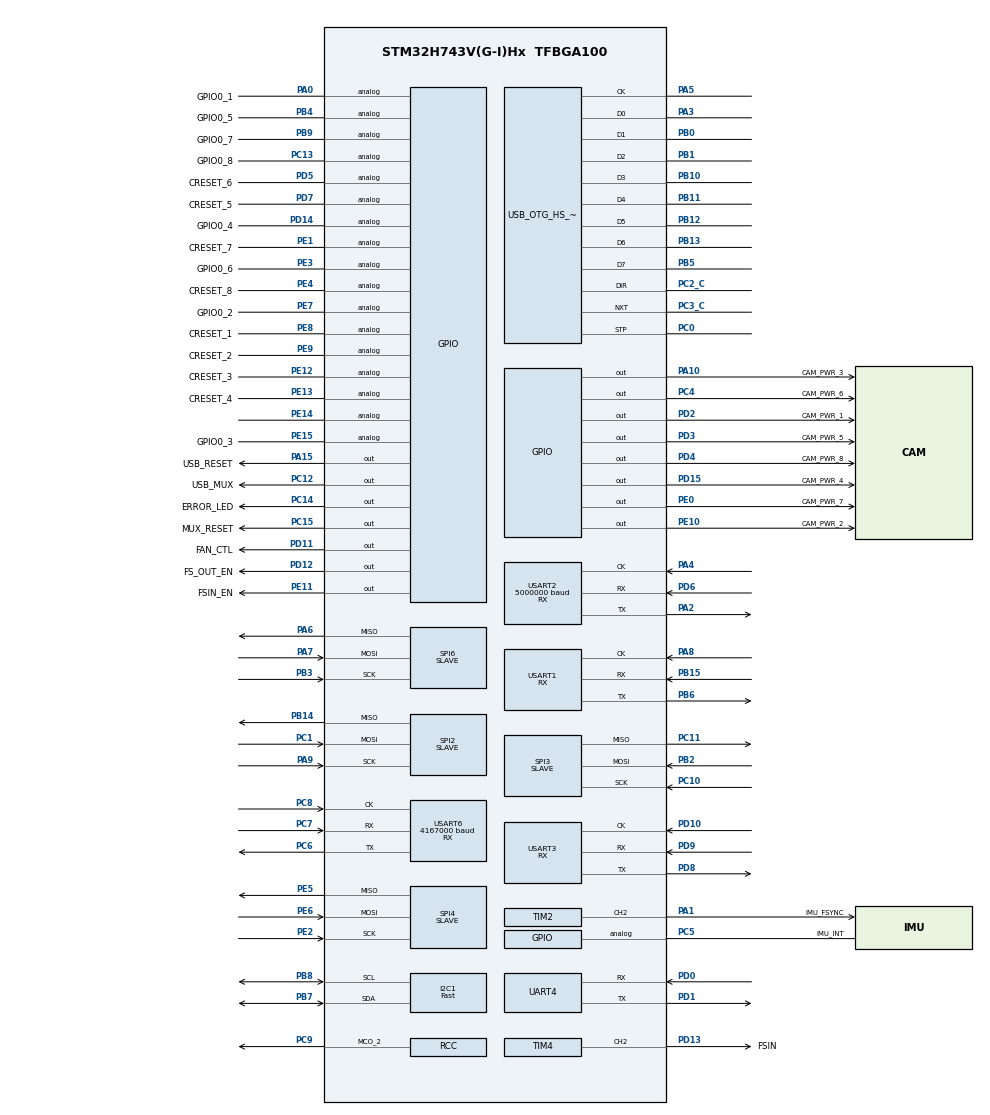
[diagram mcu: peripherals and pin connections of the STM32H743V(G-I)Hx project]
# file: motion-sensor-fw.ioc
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Bdma.Request0=SPI6_RX
Bdma.RequestsNb=1
Bdma.SPI6_RX.0.Direction=DMA_PERIPH_TO_MEMORY
Bdma.SPI6_RX.0.EventEnable=DISABLE
Bdma.SPI6_RX.0.Instance=BDMA_Channel0
Bdma.SPI6_RX.0.MemDataAlignment=DMA_MDATAALIGN_BYTE
Bdma.SPI6_RX.0.MemInc=DMA_MINC_ENABLE
Bdma.SPI6_RX.0.Mode=DMA_NORMAL
Bdma.SPI6_RX.0.PeriphDataAlignment=DMA_PDATAALIGN_BYTE
Bdma.SPI6_RX.0.PeriphInc=DMA_PINC_DISABLE
Bdma.SPI6_RX.0.Polarity=HAL_DMAMUX_REQ_GEN_RISING
Bdma.SPI6_RX.0.Priority=DMA_PRIORITY_MEDIUM
Bdma.SPI6_RX.0.RequestNumber=1
Bdma.SPI6_RX.0.SignalID=NONE
Bdma.SPI6_RX.0.SyncEnable=DISABLE
Bdma.SPI6_RX.0.SyncPolarity=HAL_DMAMUX_SYNC_NO_EVENT
Bdma.SPI6_RX.0.SyncRequestNumber=1
Bdma.SPI6_RX.0.SyncSignalID=NONE
CORTEX_M7.default_mode_Activation=1
Dma.MEMTOMEM.8.Direction=DMA_MEMORY_TO_MEMORY
Dma.MEMTOMEM.8.EventEnable=DISABLE
Dma.MEMTOMEM.8.FIFOMode=DMA_FIFOMODE_ENABLE
Dma.MEMTOMEM.8.FIFOThreshold=DMA_FIFO_THRESHOLD_FULL
Dma.MEMTOMEM.8.Instance=DMA2_Stream1
Dma.MEMTOMEM.8.MemBurst=DMA_MBURST_INC4
Dma.MEMTOMEM.8.MemDataAlignment=DMA_MDATAALIGN_WORD
Dma.MEMTOMEM.8.MemInc=DMA_MINC_ENABLE
Dma.MEMTOMEM.8.Mode=DMA_NORMAL
Dma.MEMTOMEM.8.PeriphBurst=DMA_PBURST_INC4
Dma.MEMTOMEM.8.PeriphDataAlignment=DMA_PDATAALIGN_WORD
Dma.MEMTOMEM.8.PeriphInc=DMA_PINC_DISABLE
Dma.MEMTOMEM.8.Polarity=HAL_DMAMUX_REQ_GEN_RISING
Dma.MEMTOMEM.8.Priority=DMA_PRIORITY_MEDIUM
Dma.MEMTOMEM.8.RequestNumber=1
Dma.MEMTOMEM.8.SignalID=NONE
Dma.MEMTOMEM.8.SyncEnable=DISABLE
Dma.MEMTOMEM.8.SyncPolarity=HAL_DMAMUX_SYNC_NO_EVENT
Dma.MEMTOMEM.8.SyncRequestNumber=1
Dma.MEMTOMEM.8.SyncSignalID=NONE
Dma.Request0=UART4_RX
Dma.Request1=UART4_TX
Dma.Request2=SPI2_RX
Dma.Request3=SPI4_RX
Dma.Request4=USART2_RX
Dma.Request5=USART1_RX
Dma.Request6=USART3_RX
Dma.Request7=USART6_RX
Dma.Request8=MEMTOMEM
Dma.Request9=SPI3_RX
Dma.SPI2_RX.2.Direction=DMA_PERIPH_TO_MEMORY
Dma.SPI2_RX.2.EventEnable=DISABLE
Dma.SPI2_RX.2.FIFOMode=DMA_FIFOMODE_DISABLE
Dma.SPI2_RX.2.Instance=DMA1_Stream2
Dma.SPI2_RX.2.MemDataAlignment=DMA_MDATAALIGN_BYTE
Dma.SPI2_RX.2.MemInc=DMA_MINC_ENABLE
Dma.SPI2_RX.2.Mode=DMA_NORMAL
Dma.SPI2_RX.2.PeriphDataAlignment=DMA_PDATAALIGN_BYTE
Dma.SPI2_RX.2.PeriphInc=DMA_PINC_DISABLE
Dma.SPI2_RX.2.Polarity=HAL_DMAMUX_REQ_GEN_RISING
Dma.SPI2_RX.2.Priority=DMA_PRIORITY_MEDIUM
Dma.SPI2_RX.2.RequestNumber=1
Dma.SPI2_RX.2.SignalID=NONE
Dma.SPI2_RX.2.SyncEnable=DISABLE
Dma.SPI2_RX.2.SyncPolarity=HAL_DMAMUX_SYNC_NO_EVENT
Dma.SPI2_RX.2.SyncRequestNumber=1
Dma.SPI2_RX.2.SyncSignalID=NONE
Dma.SPI3_RX.9.Direction=DMA_PERIPH_TO_MEMORY
Dma.SPI3_RX.9.EventEnable=DISABLE
Dma.SPI3_RX.9.FIFOMode=DMA_FIFOMODE_DISABLE
Dma.SPI3_RX.9.Instance=DMA1_Stream3
Dma.SPI3_RX.9.MemDataAlignment=DMA_MDATAALIGN_BYTE
Dma.SPI3_RX.9.MemInc=DMA_MINC_ENABLE
Dma.SPI3_RX.9.Mode=DMA_NORMAL
Dma.SPI3_RX.9.PeriphDataAlignment=DMA_PDATAALIGN_BYTE
Dma.SPI3_RX.9.PeriphInc=DMA_PINC_DISABLE
Dma.SPI3_RX.9.Polarity=HAL_DMAMUX_REQ_GEN_RISING
Dma.SPI3_RX.9.Priority=DMA_PRIORITY_LOW
Dma.SPI3_RX.9.RequestNumber=1
Dma.SPI3_RX.9.SignalID=NONE
Dma.SPI3_RX.9.SyncEnable=DISABLE
Dma.SPI3_RX.9.SyncPolarity=HAL_DMAMUX_SYNC_NO_EVENT
Dma.SPI3_RX.9.SyncRequestNumber=1
Dma.SPI3_RX.9.SyncSignalID=NONE
Dma.SPI4_RX.3.Direction=DMA_PERIPH_TO_MEMORY
Dma.SPI4_RX.3.EventEnable=DISABLE
Dma.SPI4_RX.3.FIFOMode=DMA_FIFOMODE_DISABLE
Dma.SPI4_RX.3.Instance=DMA1_Stream4
Dma.SPI4_RX.3.MemDataAlignment=DMA_MDATAALIGN_BYTE
Dma.SPI4_RX.3.MemInc=DMA_MINC_ENABLE
Dma.SPI4_RX.3.Mode=DMA_NORMAL
Dma.SPI4_RX.3.PeriphDataAlignment=DMA_PDATAALIGN_BYTE
Dma.SPI4_RX.3.PeriphInc=DMA_PINC_DISABLE
Dma.SPI4_RX.3.Polarity=HAL_DMAMUX_REQ_GEN_RISING
Dma.SPI4_RX.3.Priority=DMA_PRIORITY_MEDIUM
Dma.SPI4_RX.3.RequestNumber=1
Dma.SPI4_RX.3.SignalID=NONE
Dma.SPI4_RX.3.SyncEnable=DISABLE
Dma.SPI4_RX.3.SyncPolarity=HAL_DMAMUX_SYNC_NO_EVENT
Dma.SPI4_RX.3.SyncRequestNumber=1
Dma.SPI4_RX.3.SyncSignalID=NONE
Dma.UART4_RX.0.Direction=DMA_PERIPH_TO_MEMORY
Dma.UART4_RX.0.EventEnable=DISABLE
Dma.UART4_RX.0.FIFOMode=DMA_FIFOMODE_DISABLE
Dma.UART4_RX.0.Instance=DMA1_Stream0
Dma.UART4_RX.0.MemDataAlignment=DMA_MDATAALIGN_BYTE
Dma.UART4_RX.0.MemInc=DMA_MINC_ENABLE
Dma.UART4_RX.0.Mode=DMA_NORMAL
Dma.UART4_RX.0.PeriphDataAlignment=DMA_PDATAALIGN_BYTE
Dma.UART4_RX.0.PeriphInc=DMA_PINC_DISABLE
Dma.UART4_RX.0.Polarity=HAL_DMAMUX_REQ_GEN_RISING
Dma.UART4_RX.0.Priority=DMA_PRIORITY_LOW
Dma.UART4_RX.0.RequestNumber=1
Dma.UART4_RX.0.SignalID=NONE
Dma.UART4_RX.0.SyncEnable=DISABLE
Dma.UART4_RX.0.SyncPolarity=HAL_DMAMUX_SYNC_NO_EVENT
Dma.UART4_RX.0.SyncRequestNumber=1
Dma.UART4_RX.0.SyncSignalID=NONE
Dma.UART4_TX.1.Direction=DMA_MEMORY_TO_PERIPH
Dma.UART4_TX.1.EventEnable=DISABLE
Dma.UART4_TX.1.FIFOMode=DMA_FIFOMODE_DISABLE
Dma.UART4_TX.1.Instance=DMA1_Stream1
Dma.UART4_TX.1.MemDataAlignment=DMA_MDATAALIGN_BYTE
Dma.UART4_TX.1.MemInc=DMA_MINC_ENABLE
Dma.UART4_TX.1.Mode=DMA_NORMAL
Dma.UART4_TX.1.PeriphDataAlignment=DMA_PDATAALIGN_BYTE
Dma.UART4_TX.1.PeriphInc=DMA_PINC_DISABLE
Dma.UART4_TX.1.Polarity=HAL_DMAMUX_REQ_GEN_RISING
Dma.UART4_TX.1.Priority=DMA_PRIORITY_LOW
Dma.UART4_TX.1.RequestNumber=1
Dma.UART4_TX.1.SignalID=NONE
Dma.UART4_TX.1.SyncEnable=DISABLE
Dma.UART4_TX.1.SyncPolarity=HAL_DMAMUX_SYNC_NO_EVENT
Dma.UART4_TX.1.SyncRequestNumber=1
Dma.UART4_TX.1.SyncSignalID=NONE
Dma.USART1_RX.5.Direction=DMA_PERIPH_TO_MEMORY
Dma.USART1_RX.5.EventEnable=DISABLE
Dma.USART1_RX.5.FIFOMode=DMA_FIFOMODE_DISABLE
Dma.USART1_RX.5.Instance=DMA1_Stream6
Dma.USART1_RX.5.MemDataAlignment=DMA_MDATAALIGN_BYTE
Dma.USART1_RX.5.MemInc=DMA_MINC_ENABLE
Dma.USART1_RX.5.Mode=DMA_NORMAL
Dma.USART1_RX.5.PeriphDataAlignment=DMA_PDATAALIGN_BYTE
Dma.USART1_RX.5.PeriphInc=DMA_PINC_DISABLE
Dma.USART1_RX.5.Polarity=HAL_DMAMUX_REQ_GEN_RISING
Dma.USART1_RX.5.Priority=DMA_PRIORITY_MEDIUM
Dma.USART1_RX.5.RequestNumber=1
Dma.USART1_RX.5.SignalID=NONE
Dma.USART1_RX.5.SyncEnable=DISABLE
Dma.USART1_RX.5.SyncPolarity=HAL_DMAMUX_SYNC_NO_EVENT
Dma.USART1_RX.5.SyncRequestNumber=1
Dma.USART1_RX.5.SyncSignalID=NONE
Dma.USART2_RX.4.Direction=DMA_PERIPH_TO_MEMORY
Dma.USART2_RX.4.EventEnable=DISABLE
Dma.USART2_RX.4.FIFOMode=DMA_FIFOMODE_DISABLE
Dma.USART2_RX.4.Instance=DMA1_Stream5
Dma.USART2_RX.4.MemDataAlignment=DMA_MDATAALIGN_BYTE
Dma.USART2_RX.4.MemInc=DMA_MINC_ENABLE
Dma.USART2_RX.4.Mode=DMA_NORMAL
Dma.USART2_RX.4.PeriphDataAlignment=DMA_PDATAALIGN_BYTE
Dma.USART2_RX.4.PeriphInc=DMA_PINC_DISABLE
Dma.USART2_RX.4.Polarity=HAL_DMAMUX_REQ_GEN_RISING
Dma.USART2_RX.4.Priority=DMA_PRIORITY_MEDIUM
Dma.USART2_RX.4.RequestNumber=1
Dma.USART2_RX.4.SignalID=NONE
Dma.USART2_RX.4.SyncEnable=DISABLE
Dma.USART2_RX.4.SyncPolarity=HAL_DMAMUX_SYNC_NO_EVENT
Dma.USART2_RX.4.SyncRequestNumber=1
Dma.USART2_RX.4.SyncSignalID=NONE
Dma.USART3_RX.6.Direction=DMA_PERIPH_TO_MEMORY
Dma.USART3_RX.6.EventEnable=DISABLE
Dma.USART3_RX.6.FIFOMode=DMA_FIFOMODE_DISABLE
Dma.USART3_RX.6.Instance=DMA1_Stream7
Dma.USART3_RX.6.MemDataAlignment=DMA_MDATAALIGN_BYTE
Dma.USART3_RX.6.MemInc=DMA_MINC_ENABLE
Dma.USART3_RX.6.Mode=DMA_NORMAL
Dma.USART3_RX.6.PeriphDataAlignment=DMA_PDATAALIGN_BYTE
Dma.USART3_RX.6.PeriphInc=DMA_PINC_DISABLE
Dma.USART3_RX.6.Polarity=HAL_DMAMUX_REQ_GEN_RISING
Dma.USART3_RX.6.Priority=DMA_PRIORITY_MEDIUM
Dma.USART3_RX.6.RequestNumber=1
Dma.USART3_RX.6.SignalID=NONE
Dma.USART3_RX.6.SyncEnable=DISABLE
Dma.USART3_RX.6.SyncPolarity=HAL_DMAMUX_SYNC_NO_EVENT
Dma.USART3_RX.6.SyncRequestNumber=1
Dma.USART3_RX.6.SyncSignalID=NONE
Dma.USART6_RX.7.Direction=DMA_PERIPH_TO_MEMORY
Dma.USART6_RX.7.EventEnable=DISABLE
Dma.USART6_RX.7.FIFOMode=DMA_FIFOMODE_DISABLE
Dma.USART6_RX.7.Instance=DMA2_Stream0
Dma.USART6_RX.7.MemDataAlignment=DMA_MDATAALIGN_BYTE
Dma.USART6_RX.7.MemInc=DMA_MINC_ENABLE
Dma.USART6_RX.7.Mode=DMA_NORMAL
Dma.USART6_RX.7.PeriphDataAlignment=DMA_PDATAALIGN_BYTE
Dma.USART6_RX.7.PeriphInc=DMA_PINC_DISABLE
Dma.USART6_RX.7.Polarity=HAL_DMAMUX_REQ_GEN_RISING
Dma.USART6_RX.7.Priority=DMA_PRIORITY_MEDIUM
Dma.USART6_RX.7.RequestNumber=1
Dma.USART6_RX.7.SignalID=NONE
Dma.USART6_RX.7.SyncEnable=DISABLE
Dma.USART6_RX.7.SyncPolarity=HAL_DMAMUX_SYNC_NO_EVENT
Dma.USART6_RX.7.SyncRequestNumber=1
Dma.USART6_RX.7.SyncSignalID=NONE
I2C1.I2C_Speed_Mode=I2C_Fast
I2C1.Timing=0x00B03FDB
IWDG1.Prescaler=IWDG_PRESCALER_64
IWDG1.Reload=124
IWDG1.Window=4095
Mcu.Family=STM32H7
Mcu.Name=STM32H743V(G-I)Hx
Mcu.Package=TFBGA100
NVIC.BDMA_Channel0_IRQn=true\:0\:0\:false\:false\:true\:false\:true\:true
NVIC.DMA1_Stream0_IRQn=true\:0\:0\:false\:false\:true\:false\:true\:true
NVIC.DMA1_Stream1_IRQn=true\:0\:0\:false\:false\:true\:false\:true\:true
NVIC.DMA1_Stream2_IRQn=true\:0\:0\:false\:false\:true\:false\:true\:true
NVIC.DMA1_Stream3_IRQn=true\:0\:0\:false\:false\:true\:false\:true\:true
NVIC.DMA1_Stream4_IRQn=true\:0\:0\:false\:false\:true\:false\:true\:true
NVIC.DMA1_Stream5_IRQn=true\:0\:0\:false\:false\:true\:false\:true\:true
NVIC.DMA1_Stream6_IRQn=true\:0\:0\:false\:false\:true\:false\:true\:true
NVIC.DMA1_Stream7_IRQn=true\:0\:0\:false\:false\:true\:false\:true\:true
NVIC.DMA2_Stream0_IRQn=true\:0\:0\:false\:false\:true\:false\:true\:true
NVIC.ECC_IRQn=true\:0\:0\:false\:false\:true\:true\:true\:true
NVIC.I2C1_ER_IRQn=true\:0\:0\:false\:false\:true\:true\:true\:true
NVIC.I2C1_EV_IRQn=true\:0\:0\:false\:false\:true\:true\:true\:true
NVIC.OTG_HS_EP1_IN_IRQn=true\:0\:0\:false\:false\:true\:true\:true\:true
NVIC.OTG_HS_EP1_OUT_IRQn=true\:0\:0\:false\:false\:true\:true\:true\:true
NVIC.OTG_HS_IRQn=true\:0\:0\:false\:false\:true\:true\:true\:true
NVIC.PriorityGroup=NVIC_PRIORITYGROUP_4
NVIC.SPI2_IRQn=true\:0\:0\:false\:false\:true\:true\:true\:true
NVIC.SPI3_IRQn=true\:0\:0\:false\:false\:true\:true\:true\:true
NVIC.SPI4_IRQn=true\:0\:0\:false\:false\:true\:true\:true\:true
NVIC.SPI6_IRQn=true\:0\:0\:false\:false\:true\:true\:true\:true
NVIC.TIM15_IRQn=true\:0\:0\:false\:false\:true\:true\:true\:true
NVIC.TIM16_IRQn=true\:3\:0\:true\:false\:true\:true\:true\:true
NVIC.TIM17_IRQn=true\:15\:0\:false\:false\:true\:false\:true\:true
NVIC.TIM4_IRQn=true\:0\:0\:false\:false\:true\:true\:true\:true
NVIC.TIM8_BRK_TIM12_IRQn=true\:0\:0\:false\:false\:true\:true\:true\:true
NVIC.TIM8_TRG_COM_TIM14_IRQn=true\:0\:0\:false\:false\:true\:true\:true\:true
NVIC.TimeBase=TIM17_IRQn
NVIC.TimeBaseIP=TIM17
NVIC.UART4_IRQn=true\:0\:0\:false\:false\:true\:true\:true\:true
NVIC.USART1_IRQn=true\:0\:0\:false\:false\:true\:true\:true\:true
NVIC.USART2_IRQn=true\:0\:0\:false\:false\:true\:true\:true\:true
NVIC.USART3_IRQn=true\:0\:0\:false\:false\:true\:true\:true\:true
NVIC.USART6_IRQn=true\:0\:0\:false\:false\:true\:true\:true\:true
PA0.GPIO_Label=GPIO0_1
PA0.Signal=GPIO_Analog
PA1.GPIO_Label=IMU_FSYNC
PA1.Signal=S_TIM2_CH2
PA10.GPIO_Label=CAM_PWR_3
PA10.PinState=GPIO_PIN_SET
PA10.Signal=GPIO_Output
PA11.Signal=USB_OTG_FS_DM
PA12.Signal=USB_OTG_FS_DP
PA13\ (JTMS/SWDIO).Mode=Serial_Wire
PA13\ (JTMS/SWDIO).PinAttribute=Free
PA13\ (JTMS/SWDIO).Signal=DEBUG_JTMS-SWDIO
PA14\ (JTCK/SWCLK).Mode=Serial_Wire
PA14\ (JTCK/SWCLK).PinAttribute=Free
PA14\ (JTCK/SWCLK).Signal=DEBUG_JTCK-SWCLK
PA15\ (JTDI).GPIO_Label=USB_RESET
PA15\ (JTDI).PinAttribute=Free
PA15\ (JTDI).Signal=GPIO_Output
PA2.GPIO_Speed=GPIO_SPEED_FREQ_VERY_HIGH
PA2.Mode=Synchronous Slave
PA2.Signal=USART2_TX
PA3.GPIO_Speed_Only_High=GPIO_SPEED_FREQ_VERY_HIGH
PA3.Mode=Device_HS
PA3.Signal=USB_OTG_HS_ULPI_D0
PA4.GPIO_Speed=GPIO_SPEED_FREQ_VERY_HIGH
PA4.Mode=Synchronous Slave
PA4.Signal=USART2_CK
PA5.GPIO_Speed_Only_High=GPIO_SPEED_FREQ_VERY_HIGH
PA5.Mode=Device_HS
PA5.Signal=USB_OTG_HS_ULPI_CK
PA6.GPIO_Speed=GPIO_SPEED_FREQ_VERY_HIGH
PA6.Mode=Full_Duplex_Slave
PA6.Signal=SPI6_MISO
PA7.GPIO_Speed=GPIO_SPEED_FREQ_VERY_HIGH
PA7.Mode=Full_Duplex_Slave
PA7.Signal=SPI6_MOSI
PA8.GPIO_Speed=GPIO_SPEED_FREQ_VERY_HIGH
PA8.Mode=Synchronous Slave
PA8.Signal=USART1_CK
PA9.Mode=Full_Duplex_Slave
PA9.Signal=SPI2_SCK
PB0.GPIO_Speed_Only_High=GPIO_SPEED_FREQ_VERY_HIGH
PB0.Mode=Device_HS
PB0.Signal=USB_OTG_HS_ULPI_D1
PB1.GPIO_Speed_Only_High=GPIO_SPEED_FREQ_VERY_HIGH
PB1.Mode=Device_HS
PB1.Signal=USB_OTG_HS_ULPI_D2
PB10.GPIO_Speed_Only_High=GPIO_SPEED_FREQ_VERY_HIGH
PB10.Mode=Device_HS
PB10.Signal=USB_OTG_HS_ULPI_D3
PB11.GPIO_Speed_Only_High=GPIO_SPEED_FREQ_VERY_HIGH
PB11.Mode=Device_HS
PB11.Signal=USB_OTG_HS_ULPI_D4
PB12.GPIO_Speed_Only_High=GPIO_SPEED_FREQ_VERY_HIGH
PB12.Mode=Device_HS
PB12.Signal=USB_OTG_HS_ULPI_D5
PB13.GPIO_Speed_Only_High=GPIO_SPEED_FREQ_VERY_HIGH
PB13.Mode=Device_HS
PB13.Signal=USB_OTG_HS_ULPI_D6
PB14.Mode=Full_Duplex_Slave
PB14.Signal=SPI2_MISO
PB15.GPIO_Speed=GPIO_SPEED_FREQ_VERY_HIGH
PB15.Mode=Synchronous Slave
PB15.Signal=USART1_RX
PB2.Mode=Full_Duplex_Slave
PB2.Signal=SPI3_MOSI
PB3\ (JTDO/TRACESWO).GPIO_Speed=GPIO_SPEED_FREQ_VERY_HIGH
PB3\ (JTDO/TRACESWO).Mode=Full_Duplex_Slave
PB3\ (JTDO/TRACESWO).PinAttribute=Free
PB3\ (JTDO/TRACESWO).Signal=SPI6_SCK
PB4\ (NJTRST).GPIO_Label=GPIO0_5
PB4\ (NJTRST).PinAttribute=Free
PB4\ (NJTRST).Signal=GPIO_Analog
PB5.GPIO_Speed_Only_High=GPIO_SPEED_FREQ_VERY_HIGH
PB5.Mode=Device_HS
PB5.Signal=USB_OTG_HS_ULPI_D7
PB6.GPIO_Speed=GPIO_SPEED_FREQ_VERY_HIGH
PB6.Mode=Synchronous Slave
PB6.Signal=USART1_TX
PB7.Mode=I2C
PB7.PinAttribute=Free
PB7.Signal=I2C1_SDA
PB8.Mode=I2C
PB8.PinAttribute=Free
PB8.Signal=I2C1_SCL
PB9.GPIO_Label=GPIO0_7
PB9.PinAttribute=Free
PB9.Signal=GPIO_Analog
PC0.GPIO_Speed_Only_High=GPIO_SPEED_FREQ_VERY_HIGH
PC0.Mode=Device_HS
PC0.Signal=USB_OTG_HS_ULPI_STP
PC1.Mode=Full_Duplex_Slave
PC1.Signal=SPI2_MOSI
PC10.Mode=Full_Duplex_Slave
PC10.PinAttribute=Free
PC10.Signal=SPI3_SCK
PC11.Mode=Full_Duplex_Slave
PC11.PinAttribute=Free
PC11.Signal=SPI3_MISO
PC12.GPIO_Label=USB_MUX
PC12.Signal=GPIO_Output
PC13.GPIO_Label=GPIO0_8
PC13.PinAttribute=Free
PC13.Signal=GPIO_Analog
PC14-OSC32_IN\ (OSC32_IN).GPIO_Label=ERROR_LED
PC14-OSC32_IN\ (OSC32_IN).PinAttribute=Free
PC14-OSC32_IN\ (OSC32_IN).Signal=GPIO_Output
PC15-OSC32_OUT\ (OSC32_OUT).GPIO_Label=MUX_RESET
PC15-OSC32_OUT\ (OSC32_OUT).PinAttribute=Free
PC15-OSC32_OUT\ (OSC32_OUT).Signal=GPIO_Output
PC2_C.GPIO_Speed_Only_High=GPIO_SPEED_FREQ_VERY_HIGH
PC2_C.Mode=Device_HS
PC2_C.Signal=USB_OTG_HS_ULPI_DIR
PC3_C.GPIO_Speed_Only_High=GPIO_SPEED_FREQ_VERY_HIGH
PC3_C.Mode=Device_HS
PC3_C.Signal=USB_OTG_HS_ULPI_NXT
PC4.GPIO_Label=CAM_PWR_6
PC4.PinState=GPIO_PIN_SET
PC4.Signal=GPIO_Output
PC5.GPIO_Label=IMU_INT
PC5.Signal=GPIO_Analog
PC6.GPIO_Speed=GPIO_SPEED_FREQ_VERY_HIGH
PC6.Mode=Synchronous Slave
PC6.Signal=USART6_TX
PC7.GPIO_Speed=GPIO_SPEED_FREQ_VERY_HIGH
PC7.Mode=Synchronous Slave
PC7.Signal=USART6_RX
PC8.GPIO_Speed=GPIO_SPEED_FREQ_VERY_HIGH
PC8.Mode=Synchronous Slave
PC8.Signal=USART6_CK
PC9.GPIO_Speed=GPIO_SPEED_FREQ_VERY_HIGH
PC9.Mode=Clock-out-2
PC9.Signal=RCC_MCO_2
PD0.Mode=Asynchronous
PD0.Signal=UART4_RX
PD1.Mode=Asynchronous
PD1.Signal=UART4_TX
PD10.GPIO_Speed=GPIO_SPEED_FREQ_VERY_HIGH
PD10.Mode=Synchronous Slave
PD10.Signal=USART3_CK
PD11.GPIO_Label=FAN_CTL
PD11.PinState=GPIO_PIN_SET
PD11.Signal=GPIO_Output
PD12.GPIO_Label=FS_OUT_EN
PD12.PinState=GPIO_PIN_SET
PD12.Signal=GPIO_Output
PD13.GPIO_Label=FSIN
PD13.GPIO_PuPd=GPIO_PULLDOWN
PD13.Signal=S_TIM4_CH2
PD14.GPIO_Label=GPIO0_4
PD14.Signal=GPIO_Analog
PD15.GPIO_Label=CAM_PWR_4
PD15.PinState=GPIO_PIN_SET
PD15.Signal=GPIO_Output
PD2.GPIO_Label=CAM_PWR_1
PD2.PinState=GPIO_PIN_SET
PD2.Signal=GPIO_Output
PD3.GPIO_Label=CAM_PWR_5
PD3.PinState=GPIO_PIN_SET
PD3.Signal=GPIO_Output
PD4.GPIO_Label=CAM_PWR_8
PD4.PinState=GPIO_PIN_SET
PD4.Signal=GPIO_Output
PD5.GPIO_Label=CRESET_6
PD5.PinAttribute=Free
PD5.Signal=GPIO_Analog
PD6.GPIO_Speed=GPIO_SPEED_FREQ_VERY_HIGH
PD6.Mode=Synchronous Slave
PD6.Signal=USART2_RX
PD7.GPIO_Label=CRESET_5
PD7.Signal=GPIO_Analog
PD8.GPIO_Speed=GPIO_SPEED_FREQ_VERY_HIGH
PD8.Mode=Synchronous Slave
PD8.Signal=USART3_TX
PD9.GPIO_Speed=GPIO_SPEED_FREQ_VERY_HIGH
PD9.Mode=Synchronous Slave
PD9.Signal=USART3_RX
PE0.GPIO_Label=CAM_PWR_7
PE0.PinState=GPIO_PIN_SET
PE0.Signal=GPIO_Output
PE1.GPIO_Label=CRESET_7
PE1.Signal=GPIO_Analog
PE10.GPIO_Label=CAM_PWR_2
PE10.PinState=GPIO_PIN_SET
PE10.Signal=GPIO_Output
PE11.GPIO_Label=FSIN_EN
PE11.PinState=GPIO_PIN_SET
PE11.Signal=GPIO_Output
PE12.GPIO_Label=CRESET_3
PE12.Signal=GPIO_Analog
PE13.GPIO_Label=CRESET_4
PE13.Signal=GPIO_Analog
PE14.Signal=GPIO_Analog
PE15.GPIO_Label=GPIO0_3
PE15.Signal=GPIO_Analog
PE2.Mode=Full_Duplex_Slave
PE2.PinAttribute=Free
PE2.Signal=SPI4_SCK
PE3.GPIO_Label=GPIO0_6
PE3.PinAttribute=Free
PE3.Signal=GPIO_Analog
PE4.GPIO_Label=CRESET_8
PE4.Signal=GPIO_Analog
PE5.Mode=Full_Duplex_Slave
PE5.Signal=SPI4_MISO
PE6.Mode=Full_Duplex_Slave
PE6.Signal=SPI4_MOSI
PE7.GPIO_Label=GPIO0_2
PE7.Signal=GPIO_Analog
PE8.GPIO_Label=CRESET_1
PE8.Signal=GPIO_Analog
PE9.GPIO_Label=CRESET_2
PE9.Signal=GPIO_Analog
PH0-OSC_IN\ (PH0).Mode=HSE-External-Oscillator
PH0-OSC_IN\ (PH0).Signal=RCC_OSC_IN
PH1-OSC_OUT\ (PH1).Mode=HSE-External-Oscillator
PH1-OSC_OUT\ (PH1).Signal=RCC_OSC_OUT
ProjectManager.HeapSize=0x400
ProjectManager.StackSize=0x800
ProjectManager.TargetToolchain=CMake
RAMECC.Instance-RAMECC1_Monitor1=RAMECC1_Monitor1
RAMECC.Instance-RAMECC1_Monitor2=RAMECC1_Monitor2
RAMECC.Instance-RAMECC1_Monitor3=RAMECC1_Monitor3
RAMECC.Instance-RAMECC1_Monitor4=RAMECC1_Monitor4
RAMECC.Instance-RAMECC1_Monitor5=RAMECC1_Monitor5
RAMECC.Instance-RAMECC2_Monitor1=RAMECC2_Monitor1
RAMECC.Instance-RAMECC2_Monitor2=RAMECC2_Monitor2
RAMECC.Instance-RAMECC2_Monitor3=RAMECC2_Monitor3
RAMECC.Instance-RAMECC2_Monitor4=RAMECC2_Monitor4
RAMECC.Instance-RAMECC2_Monitor5=RAMECC2_Monitor5
RAMECC.Instance-RAMECC3_Monitor1=RAMECC3_Monitor1
RAMECC.Instance-RAMECC3_Monitor2=RAMECC3_Monitor2
RCC.ADCFreq_Value=120000000
RCC.APB1Freq_Value=120000000
RCC.APB2Freq_Value=120000000
RCC.APB3Freq_Value=120000000
RCC.APB4Freq_Value=120000000
RCC.CortexFreq_Value=480000000
RCC.D1PPRE=RCC_APB3_DIV2
RCC.D2PPRE1=RCC_APB1_DIV2
RCC.D2PPRE2=RCC_APB2_DIV2
RCC.D3PPRE=RCC_APB4_DIV2
RCC.DIVM1=3
RCC.DIVM2=6
RCC.DIVM3=6
RCC.DIVN1=120
RCC.DIVN2=120
RCC.DIVN3=120
RCC.DIVP2=4
RCC.DIVQ1=20
RCC.DIVQ3=10
RCC.HCLKFreq_Value=240000000
RCC.HPRE=RCC_HCLK_DIV2
RCC.HSE_VALUE=24000000
RCC.PLLSourceVirtual=RCC_PLLSOURCE_HSE
RCC.RCC_MCO2Source=RCC_MCO2SOURCE_PLL2PCLK
RCC.RCC_MCODiv2=RCC_MCODIV_5
RCC.RNGCLockSelection=RCC_RNGCLKSOURCE_PLL
RCC.SPI123CLockSelection=RCC_SPI123CLKSOURCE_PLL2
RCC.SYSCLKFreq_VALUE=480000000
RCC.SYSCLKSource=RCC_SYSCLKSOURCE_PLLCLK
RCC.SupplySource=PWR_LDO_SUPPLY
RCC.USBFreq_Value=48000000
RCC.VDD_VALUE=1.8
SH.S_TIM2_CH2.0=TIM2_CH2,PWM Generation2 CH2
SH.S_TIM4_CH2.0=TIM4_CH2,PWM Generation2 CH2
SPI2.CLKPhase=SPI_PHASE_2EDGE
SPI2.CLKPolarity=SPI_POLARITY_HIGH
SPI2.DataSize=SPI_DATASIZE_8BIT
SPI2.Direction=SPI_DIRECTION_2LINES
SPI2.FirstBit=SPI_FIRSTBIT_LSB
SPI2.Mode=SPI_MODE_SLAVE
SPI2.VirtualType=VM_SLAVE
SPI3.CLKPhase=SPI_PHASE_2EDGE
SPI3.CLKPolarity=SPI_POLARITY_HIGH
SPI3.DataSize=SPI_DATASIZE_8BIT
SPI3.Direction=SPI_DIRECTION_2LINES
SPI3.FirstBit=SPI_FIRSTBIT_LSB
SPI3.Mode=SPI_MODE_SLAVE
SPI3.VirtualType=VM_SLAVE
SPI4.CLKPhase=SPI_PHASE_2EDGE
SPI4.CLKPolarity=SPI_POLARITY_HIGH
SPI4.DataSize=SPI_DATASIZE_8BIT
SPI4.Direction=SPI_DIRECTION_2LINES
SPI4.FirstBit=SPI_FIRSTBIT_LSB
SPI4.Mode=SPI_MODE_SLAVE
SPI4.VirtualType=VM_SLAVE
SPI6.CLKPhase=SPI_PHASE_2EDGE
SPI6.CLKPolarity=SPI_POLARITY_HIGH
SPI6.DataSize=SPI_DATASIZE_8BIT
SPI6.Direction=SPI_DIRECTION_2LINES
SPI6.FirstBit=SPI_FIRSTBIT_LSB
SPI6.Mode=SPI_MODE_SLAVE
SPI6.VirtualType=VM_SLAVE
TIM14.Period=25000-1
TIM14.Prescaler=240-1
TIM15.Prescaler=240-1
TIM16.Period=25000-1
TIM16.Prescaler=240-1
TIM2.Channel-PWM\ Generation2\ CH2=TIM_CHANNEL_2
TIM4.Channel-Output\ Compare3\ No\ Output=TIM_CHANNEL_3
TIM4.Channel-PWM\ Generation2\ CH2=TIM_CHANNEL_2
TIM4.OCPolarity_2=TIM_OCPOLARITY_LOW
TIM4.Period=5999
TIM4.Prescaler=1000
TIM4.Pulse-Output\ Compare3\ No\ Output=3000
TIM4.Pulse-PWM\ Generation2\ CH2=3000
TIM5.Period=0xFFFFFFFF
TIM5.Prescaler=2400-1
TIM8.Period=10-1
TIM8.Prescaler=0
USART1.CLKPhase=USART_PHASE_2EDGE
USART1.CLKPolarity=USART_POLARITY_HIGH
USART1.FIFOMode=FIFOMODE_ENABLE
USART1.Mode=MODE_RX
USART1.RXFIFOThreshold=RXFIFO_THRESHOLD_FULL
USART1.VirtualMode-Synchronous\ Slave=VM_SYNC
USART2.BaudRate=5000000
USART2.CLKPhase=USART_PHASE_2EDGE
USART2.CLKPolarity=USART_POLARITY_HIGH
USART2.FIFOMode=FIFOMODE_ENABLE
USART2.Mode=MODE_RX
USART2.RXFIFOThreshold=RXFIFO_THRESHOLD_FULL
USART2.VirtualMode-Synchronous\ Slave=VM_SYNC
USART3.CLKPhase=USART_PHASE_2EDGE
USART3.CLKPolarity=USART_POLARITY_HIGH
USART3.FIFOMode=FIFOMODE_ENABLE
USART3.Mode=MODE_RX
USART3.RXFIFOThreshold=RXFIFO_THRESHOLD_FULL
USART3.VirtualMode-Synchronous\ Slave=VM_SYNC
USART6.BaudRate=4167000
USART6.CLKPhase=USART_PHASE_2EDGE
USART6.CLKPolarity=USART_POLARITY_HIGH
USART6.FIFOMode=FIFOMODE_ENABLE
USART6.Mode=MODE_RX
USART6.RXFIFOThreshold=RXFIFO_THRESHOLD_FULL
USART6.VirtualMode=VM_SYNC
USB_OTG_HS.DeviceSpeed-Device_HS=PCD_SPEED_HIGH
USB_OTG_HS.VirtualMode-Device_HS=Device_HS
VP_CRC_VS_CRC.Mode=CRC_Activate
VP_IWDG1_VS_IWDG.Mode=IWDG_Activate
VP_MEMORYMAP_VS_MEMORYMAP.Mode=CurAppReg
VP_RAMECC_VS_D1_1.Mode=RAMECC1_Monitor1
VP_RAMECC_VS_D1_2.Mode=RAMECC1_Monitor2
VP_RAMECC_VS_D1_3.Mode=RAMECC1_Monitor3
VP_RAMECC_VS_D1_4.Mode=RAMECC1_Monitor4
VP_RAMECC_VS_D1_5.Mode=RAMECC1_Monitor5
VP_RAMECC_VS_D2_1.Mode=RAMECC2_Monitor1
VP_RAMECC_VS_D2_2.Mode=RAMECC2_Monitor2
VP_RAMECC_VS_D2_3.Mode=RAMECC2_Monitor3
VP_RAMECC_VS_D2_4.Mode=RAMECC2_Monitor4
VP_RAMECC_VS_D2_5.Mode=RAMECC2_Monitor5
VP_RAMECC_VS_D3_1.Mode=RAMECC3_Monitor1
VP_RAMECC_VS_D3_2.Mode=RAMECC3_Monitor2
VP_RNG_VS_RNG.Mode=RNG_Activate
VP_SYS_VS_tim17.Mode=TIM17
VP_TIM14_VS_ClockSourceINT.Mode=Enable_Timer
VP_TIM15_VS_ClockSourceINT.Mode=Internal
VP_TIM16_VS_ClockSourceINT.Mode=Enable_Timer
VP_TIM2_VS_ClockSourceINT.Mode=Internal
VP_TIM4_VS_no_output3.Mode=Output Compare3 No Output
VP_TIM5_VS_ClockSourceINT.Mode=Internal
VP_TIM8_VS_ClockSourceINT.Mode=Internal
board=custom

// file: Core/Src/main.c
/* USER CODE BEGIN Header */
/**
 ******************************************************************************
 * @file           : main.c
 * @brief          : Main program body
 ******************************************************************************
 * @attention
 *
 * Copyright (c) 2024 STMicroelectronics.
 * All rights reserved.
 *
 * This software is licensed under terms that can be found in the LICENSE file
 * in the root directory of this software component.
 * If no LICENSE file comes with this software, it is provided AS-IS.
 *
 ******************************************************************************
 */
/* USER CODE END Header */
#include "main.h"

/* USER CODE BEGIN Includes */
#include "0X02C1B.h"
#include "usb_device.h"
#include "uart_comms.h"
#include "usbd_histo.h"
#include "usbd_imu.h"
#include "usbd_comms.h"
#include "logging.h"
#include "utils.h"
#include "i2c_master.h"
#include "i2c_health.h"
#include "histo_fake.h"
#include "ICM20948.h"
#include "camera_manager.h"
#include "system_monitor.h"
#include "common.h"        /* DEBUG_FLAG_* (e.g. DEBUG_FLAG_SEND_DEFER) */

#include <stdio.h>
#include <string.h>
#include <stdbool.h>

#include "stm32h7xx_ll_tim.h"

/* USER CODE END Includes */

/* USER CODE BEGIN PTD */

/* External references to USB endpoint status variables */
extern volatile uint8_t tx_flag;  // From uart_comms.c
extern volatile uint8_t comms_ep_data;  // From usbd_comms.c (__IO is volatile)
extern volatile uint8_t histo_ep_data;  // From usbd_histo.c (__IO is volatile)
extern volatile uint8_t imu_ep_data;    // From usbd_imu.c (__IO is volatile)

/* USER CODE END PTD */

CRC_HandleTypeDef hcrc;

I2C_HandleTypeDef hi2c1;

IWDG_HandleTypeDef hiwdg1;

RAMECC_HandleTypeDef hramecc1_m1;
RAMECC_HandleTypeDef hramecc1_m2;
RAMECC_HandleTypeDef hramecc1_m3;
RAMECC_HandleTypeDef hramecc1_m4;
RAMECC_HandleTypeDef hramecc1_m5;
RAMECC_HandleTypeDef hramecc2_m1;
RAMECC_HandleTypeDef hramecc2_m2;
RAMECC_HandleTypeDef hramecc2_m3;
RAMECC_HandleTypeDef hramecc2_m4;
RAMECC_HandleTypeDef hramecc2_m5;
RAMECC_HandleTypeDef hramecc3_m1;
RAMECC_HandleTypeDef hramecc3_m2;

RNG_HandleTypeDef hrng;

SPI_HandleTypeDef hspi2;
SPI_HandleTypeDef hspi3;
SPI_HandleTypeDef hspi4;
SPI_HandleTypeDef hspi6;
DMA_HandleTypeDef hdma_spi2_rx;
DMA_HandleTypeDef hdma_spi3_rx;
DMA_HandleTypeDef hdma_spi4_rx;
DMA_HandleTypeDef hdma_spi6_rx;

TIM_HandleTypeDef htim2;
TIM_HandleTypeDef htim4;
TIM_HandleTypeDef htim5;
TIM_HandleTypeDef htim8;
TIM_HandleTypeDef htim14;
TIM_HandleTypeDef htim15;
TIM_HandleTypeDef htim16;

UART_HandleTypeDef huart4;
USART_HandleTypeDef husart1;
USART_HandleTypeDef husart2;
USART_HandleTypeDef husart3;
USART_HandleTypeDef husart6;
DMA_HandleTypeDef hdma_uart4_rx;
DMA_HandleTypeDef hdma_uart4_tx;
DMA_HandleTypeDef hdma_usart1_rx;
DMA_HandleTypeDef hdma_usart2_rx;
DMA_HandleTypeDef hdma_usart3_rx;
DMA_HandleTypeDef hdma_usart6_rx;

DMA_HandleTypeDef hdma_memtomem_dma2_stream1;
/* USER CODE BEGIN PV */

uint8_t rxBuffer[COMMAND_MAX_SIZE]  __attribute__((aligned(4)));
uint8_t txBuffer[COMMAND_MAX_SIZE];
#if FPGA_HOST_UPLOAD
/* Host-uploaded camera bitstream (Debug builds only, #136). */
uint32_t bitstream_len;
__attribute__((section(".RAM_D1"))) uint8_t bitstream_buffer[MAX_BITSTREAM_SIZE]; // 160KB buffer
#endif

volatile uint8_t event_bits = 0x00;         // holds the event bits to be flipped
volatile uint8_t event_bits_enabled = 0x00; // holds the event bits for the cameras to be enabled
volatile uint16_t pulse_count = 0;
extern volatile uint32_t imu_frame_counter;
volatile bool _enter_dfu = false;
volatile uint8_t imu_sample_due = 0; // set by the TIM14 ISR, serviced by imu_service()
/* #68 experiment: when DEBUG_FLAG_SEND_DEFER is active, the FSIN ISRs only set this
 * flag and the main loop runs send_data() — moving the heavy per-frame send out of
 * interrupt context so it can't block/starve the camera SPI/USART transport IRQs. */
volatile bool send_data_flag = false;
/* #68: histogram-frame timestamp captured at the FSIN rising edge (in the ISR).
 * The send path uses this instead of sampling the clock itself, so the packet
 * timestamp reflects the frame-sync instant even when the send is deferred to
 * the main loop (where it would otherwise lag by the main-loop service latency). */
volatile uint32_t fsin_timestamp_ms = 0;

ICM_Axis3D a;
ICM_Axis3D m;
ICM_Axis3D g;
float t;
char usb_buf[128];
// Debug flags (sensor debug and fake data are controlled via OW_CMD_DEBUG_FLAGS)
bool uart_stream = false;

uint16_t fail_count = 0;

extern USBD_HandleTypeDef hUsbDeviceHS;

const char *bit_rep[16] = {
    [ 0] = "0000", [ 1] = "0001", [ 2] = "0010", [ 3] = "0011",
    [ 4] = "0100", [ 5] = "0101", [ 6] = "0110", [ 7] = "0111",
    [ 8] = "1000", [ 9] = "1001", [10] = "1010", [11] = "1011",
    [12] = "1100", [13] = "1101", [14] = "1110", [15] = "1111",
};
/* USER CODE END PV */

void SystemClock_Config(void);
void PeriphCommonClock_Config(void);
static void MPU_Config(void);
static void MX_GPIO_Init(void);
static void MX_DMA_Init(void);
static void MX_BDMA_Init(void);
static void MX_CRC_Init(void);
static void MX_I2C1_Init(void);
static void MX_RNG_Init(void);
static void MX_SPI2_Init(void);
static void MX_SPI3_Init(void);
static void MX_SPI4_Init(void);
static void MX_SPI6_Init(void);
static void MX_TIM2_Init(void);
static void MX_UART4_Init(void);
static void MX_USART6_Init(void);
static void MX_TIM8_Init(void);
static void MX_TIM4_Init(void);
static void MX_USART1_Init(void);
static void MX_USART2_Init(void);
static void MX_USART3_Init(void);
static void MX_TIM14_Init(void);
static void MX_TIM16_Init(void);
static void MX_TIM5_Init(void);
static void MX_TIM15_Init(void);
static void MX_IWDG1_Init(void);
static void MX_RAMECC_Init(void);
/* USER CODE BEGIN PFP */
static void imu_service(void);
/* USER CODE END PFP */

/* USER CODE BEGIN 0 */
/*
 * IWDG1 has a 250 ms window (MX_IWDG1_Init, #136). The main loop feeds it once
 * per pass, so any single fixed wait or bounded hardware operation that can
 * run longer than that has to feed it as it goes: delay_ms_fed() cuts a wait
 * into slices with a refresh between them. Only bounded waits may feed; a
 * loop that can spin forever must not, or it would hide the hang the watchdog
 * is there to catch.
 */
void watchdog_feed(void)
{
  HAL_IWDG_Refresh(&hiwdg1);
}

void delay_ms_fed(uint32_t ms)
{
  while (ms > 0U) {
    uint32_t slice = (ms > 50U) ? 50U : ms;
    HAL_IWDG_Refresh(&hiwdg1);
    delay_ms(slice);
    ms -= slice;
  }
  HAL_IWDG_Refresh(&hiwdg1);
}

/*
 * Clear the custom secure bootloader's failsafe boot counter (RTC->BKP6R).
 * The bootloader increments BKP6R on every launch attempt; after
 * BL_BOOT_FAIL_MAX consecutive attempts that do not clear it, it enters USB DFU
 * instead of launching us. Calling this early in boot signals a successful
 * launch so the next normal reset starts from a clean count. No-op in bare-metal
 * (no bootloader). HAL RTC module is not enabled, so use CMSIS directly. */
#if !defined(BARE_METAL_BUILD)
static void clear_boot_counter(void)
{
  PWR->CR1     |= PWR_CR1_DBP;            /* disable backup-domain write protect  */
  RCC->APB4ENR |= RCC_APB4ENR_RTCAPBEN;  /* RTC register APB interface clock      */
  RCC->CSR     |= RCC_CSR_LSION;          /* LSI on (RTC kernel clock source)      */
  { uint32_t to = 0U;
    while (((RCC->CSR & RCC_CSR_LSIRDY) == 0U) && (++to < 0x00100000U)) { } }
  if ((RCC->BDCR & RCC_BDCR_RTCSEL) == 0U) {
    RCC->BDCR = (RCC->BDCR & ~RCC_BDCR_RTCSEL) | RCC_BDCR_RTCSEL_1; /* LSI */
  }
  RCC->BDCR |= RCC_BDCR_RTCEN;            /* enable RTC                            */
  RTC->BKP6R = 0U;                        /* successful boot: reset the attempt count */
  __DSB();
}
#endif /* !BARE_METAL_BUILD */

/* Print last reset cause - helps diagnose thermal/brownout (BOR) or watchdog (IWDG) */
static void print_reset_cause(void)
{
	uint8_t first = 1;
	if (__HAL_RCC_GET_FLAG(RCC_FLAG_BORRST)) {
		printf("Reset cause: BOR (Brown-Out) - possible thermal/voltage droop\r\n");
		first = 0;
	}
	if (__HAL_RCC_GET_FLAG(RCC_FLAG_PORRST)) {
		printf("%sReset cause: POR (Power-On)\r\n", first ? "" : "         ");
		first = 0;
	}
	if (__HAL_RCC_GET_FLAG(RCC_FLAG_PINRST)) {
		printf("%sReset cause: PIN (External NRST)\r\n", first ? "" : "         ");
		first = 0;
	}
	if (__HAL_RCC_GET_FLAG(RCC_FLAG_SFTRST)) {
		printf("%sReset cause: Software\r\n", first ? "" : "         ");
		first = 0;
	}
#if defined(RCC_FLAG_IWDG1RST)
	if (__HAL_RCC_GET_FLAG(RCC_FLAG_IWDG1RST)) {
		printf("%sReset cause: IWDG (Independent Watchdog) - possible lockup/thermal\r\n", first ? "" : "         ");
		first = 0;
	}
#endif
#if defined(RCC_FLAG_WWDG1RST)
	if (__HAL_RCC_GET_FLAG(RCC_FLAG_WWDG1RST)) {
		printf("%sReset cause: WWDG (Window Watchdog)\r\n", first ? "" : "         ");
		first = 0;
	}
#endif
#if defined(RCC_FLAG_LPWR1RST)
	if (__HAL_RCC_GET_FLAG(RCC_FLAG_LPWR1RST)) {
		printf("%sReset cause: LPWR (Low-power)\r\n", first ? "" : "         ");
		first = 0;
	}
#endif
	if (first) {
		printf("Reset cause: unknown\r\n");
	}
	__HAL_RCC_CLEAR_RESET_FLAGS();
}

/* Poll MCU junction temperature; print warning if above high threshold */
#define MCU_TEMP_CHECK_MS  5000u
static void poll_mcu_temperature(void)
{
	static uint32_t last_check_ms = 0;
	uint32_t now = HAL_GetTick();
	if ((last_check_ms != 0u) && ((now - last_check_ms) < MCU_TEMP_CHECK_MS)) {
		return;
	}
	last_check_ms = now;
	uint32_t level = HAL_PWREx_GetTemperatureLevel();
	if (level == PWR_TEMP_ABOVE_HIGH_THRESHOLD) {
		printf("[THERMAL] MCU junction temp ABOVE HIGH THRESHOLD - reduce load/cooling!\r\n");
	}
}

static void PrintI2CSpeed(I2C_HandleTypeDef *hi2c)
{
  // Assuming the timing is configured in I2C_TIMINGR register
  uint32_t timing = hi2c->Init.Timing;
  uint32_t presc = (timing >> 28) & 0xF;
  uint32_t scll = (timing >> 0) & 0xFF;
  uint32_t sclh = (timing >> 8) & 0xFF;

  // Get the I2C clock source frequency
  uint32_t i2c_clk_freq = HAL_RCC_GetPCLK1Freq();

  // Calculate SCL speed (frequency) in Hz
  uint32_t scl_freq = i2c_clk_freq / ((presc + 1) * (scll + 1 + sclh + 1));

  // Print I2C speed
  printf("I2C Speed: %lu Hz\r\n", scl_freq); // Print the I2C speed in kHz
}

/* USER CODE END 0 */

int main(void)
{

  /* MPU Configuration--------------------------------------------------------*/
  MPU_Config();

  /* MCU Configuration--------------------------------------------------------*/

  /* Reset of all peripherals, Initializes the Flash interface and the Systick. */
  HAL_Init();

  /* Configure the system clock */
  SystemClock_Config();

  /* Configure the peripherals common clocks */
  PeriphCommonClock_Config();

  /* Initialize all configured peripherals */
  MX_GPIO_Init();
  MX_DMA_Init();
  MX_BDMA_Init();
  MX_CRC_Init();
  MX_I2C1_Init();
  MX_RNG_Init();
  MX_SPI2_Init();
  MX_SPI3_Init();
  MX_SPI4_Init();
  MX_SPI6_Init();
  MX_TIM2_Init();
  MX_UART4_Init();
  MX_USART6_Init();
  MX_TIM8_Init();
  MX_TIM4_Init();
  MX_USART1_Init();
  MX_USART2_Init();
  MX_USART3_Init();
  MX_TIM14_Init();
  MX_TIM16_Init();
  MX_TIM5_Init();
  MX_TIM15_Init();
  MX_IWDG1_Init();
  MX_RAMECC_Init();
  /* USER CODE BEGIN 2 */
#if DEBUG_ENABLED
  /* Stop IWDG1 while the core is halted by a debugger. With the 250 ms window
   * (#136) a breakpoint would otherwise reset the module almost at once. */
  __HAL_DBGMCU_FREEZE_IWDG1();
#endif
#if (DEBUG_ENABLED == 0) && !defined(BARE_METAL_BUILD)
  /* Debug port stays closed (PTR-2026-1-5 CON-02, CVE-1191). The secure bootloader
   * reconfigures PA13/PA14 (SWDIO/SWCLK) as plain inputs before launching us (DAP
   * lock). Nothing in this application uses PA13/PA14, but assert the state here
   * too so that a bootloader without the lock, or a future GPIO change, can never
   * leave the probe interface live on a Release unit. Analog mode: no input
   * buffer, no pull, lowest leakage. Debug builds keep SWD for development;
   * bare-metal builds have no bootloader in front of them and are not fielded.
   * Same change as openmotion-console-fw (ECO secure-boot 1.2.0, section 4). */
  {
    GPIO_InitTypeDef swd = {0};
    __HAL_RCC_GPIOA_CLK_ENABLE();
    swd.Pin  = GPIO_PIN_13 | GPIO_PIN_14;
    swd.Mode = GPIO_MODE_ANALOG;
    swd.Pull = GPIO_NOPULL;
    HAL_GPIO_Init(GPIOA, &swd);
  }
#endif

  if (HAL_TIM_Base_Start(&htim5) != HAL_OK)
  {
    Error_Handler();
  }

  init_dma_logging();

  DWT_Init();

  // enable I2C MUX
  HAL_GPIO_WritePin(MUX_RESET_GPIO_Port, MUX_RESET_Pin, GPIO_PIN_RESET);

  // enable USB PHY
  HAL_GPIO_WritePin(USB_RESET_GPIO_Port, USB_RESET_Pin, GPIO_PIN_RESET);

  printf("\033c");
  fflush(stdout);
  delay_ms_fed(500);
  printf("Openwater open-MOTION Aggregator\r\n\r\n");
  printf("FW: %s (%s)\r\nDate: %s\r\n",
       FW_VERSION_STRING,
       FW_SHA_STRING,
       FW_BUILD_TIME_STRING);
  printf("CPU Clock Frequency: %lu MHz\r\n",
         HAL_RCC_GetSysClockFreq() / 1000000);
  system_monitor_capture_reset_cause();
  print_reset_cause();
  system_monitor_print_history();
  system_monitor_ecc_enable();
  HAL_PWREx_EnableMonitoring();  /* Enable junction temp (TEMPH/TEMPL) monitoring */
  printf("Initializing, please wait ...\r\n");

#if !defined(BARE_METAL_BUILD)
  /* Signal a successful launch to the custom bootloader (clears its failsafe
   * boot counter) early, before the camera/FPGA bring-up below, so a stalled
   * FPGA init (e.g. bitstream not yet flashed) does not trip the DFU fallback. */
  clear_boot_counter();
#endif

  // enable HS USB MUX
  HAL_GPIO_WritePin(USB_MUX_GPIO_Port, USB_MUX_Pin, GPIO_PIN_RESET);

  // enable I2C MUX
  HAL_GPIO_WritePin(MUX_RESET_GPIO_Port, MUX_RESET_Pin, GPIO_PIN_SET);

  HAL_GPIO_WritePin(FS_OUT_EN_GPIO_Port, FS_OUT_EN_Pin, GPIO_PIN_RESET);  //enable Framesync output

  // test i2c
  PrintI2CSpeed(&hi2c1);
  // I2C_scan(&hi2c1, NULL, 0, true);
  delay_ms_fed(100);
  X02C1B_FSIN_EXT_disable();
  GPIO_SetOutput(FSIN_EN_GPIO_Port, FSIN_EN_Pin, GPIO_PIN_RESET); // disable fsin output

  if (ICM_WHOAMI() == ICM20948_EXPECTED_ID)
  {
	/* ICM_Init() carries ~185 ms of fixed waits: feed right before it. */
	watchdog_feed();
	if(ICM_Init() != HAL_OK){
		printf("Failed to initialize IMU\r\n\n");
	}
	else
	{
		printf("IMU detected\r\n");
	    delay_ms_fed(100);
	    if(verbose_on) ICM_DumpRegisters();
	}
  }
  else
  {
    printf("IMU NOT detected\r\n\n");
  }

  delay_ms_fed(10);

  HAL_GPIO_WritePin(USB_RESET_GPIO_Port, USB_RESET_Pin, GPIO_PIN_SET);

  HAL_GPIO_WritePin(ERROR_LED_GPIO_Port, ERROR_LED_Pin, GPIO_PIN_SET);

  init_camera_sensors(); // init structures and camera configs

  /* Boot-time I2C health scan: bring up each camera/FPGA one at a time and
   * verify mux, IMU, all 8 cameras and FPGAs respond. Caches a snapshot the
   * host can read via OW_CMD_I2C_STATUS. Leaves all cameras powered off. */
  i2c_health_scan();
  HAL_IWDG_Refresh(&hiwdg1);

  // Select default camera
  TCA9548A_SelectChannel(&hi2c1, 0x70, get_active_cam()->i2c_target);

  delay_ms_fed(250);
  MX_USB_DEVICE_Init();
  delay_ms_fed(1000);
  //GPIO_SetHiZ(GPIOA, GPIO_PIN_2);

  comms_host_start();
  // fill_frame_buffers();
  HAL_IWDG_Refresh(&hiwdg1);
  printf("System Running\r\n");
  /* USER CODE END 2 */

  /* Infinite loop */
  while (1)
  {

    /* USER CODE BEGIN 3 */
    /* #68 experiment: run the deferred per-frame send in thread context (set by the
     * FSIN ISR when DEBUG_FLAG_SEND_DEFER is active). Runs below every interrupt, so it
     * cannot block the camera SPI/USART transport IRQs the way the ISR-context send does. */
    if (send_data_flag) { send_data_flag = false; send_data(); }
  	comms_host_check_received(); // check comms
    imu_service();           /* Sample the ICM if the 200 Hz timer ticked */
    camera_i2c_service();    /* Camera-bus work deferred from the frame ISRs (temp poll, mux disables) */
    camera_rearm_service();  /* #116: retry any camera RX arm that failed in PendSV (abort+backoff) */
    logging_pump();          /* Flush USB log data buffered from ISR context */
    check_streaming();
    USBD_HISTO_CheckTxStuck(); /* Recover the HISTO EP if an armed transfer stalls (dead host reader) */
    poll_mcu_temperature();  /* Print warning if MCU junction temp above threshold */
    USB_RecoveryCheck();     /* EFT/lock-up watchdog: rebuild USB stack if bus goes dead */
    system_monitor_poll();   /* ECC report drain + DMA error-flag scan */
    HAL_IWDG_Refresh(&hiwdg1);
  }

  /* USER CODE END 3 */
}

void SystemClock_Config(void)
{
  RCC_OscInitTypeDef RCC_OscInitStruct = {0};
  RCC_ClkInitTypeDef RCC_ClkInitStruct = {0};

  /** Supply configuration update enable
  */
  HAL_PWREx_ConfigSupply(PWR_LDO_SUPPLY);

  /** Configure the main internal regulator output voltage
  */
  __HAL_PWR_VOLTAGESCALING_CONFIG(PWR_REGULATOR_VOLTAGE_SCALE0);

  while(!__HAL_PWR_GET_FLAG(PWR_FLAG_VOSRDY)) {}

  /** Initializes the RCC Oscillators according to the specified parameters
  * in the RCC_OscInitTypeDef structure.
  */
  RCC_OscInitStruct.OscillatorType = RCC_OSCILLATORTYPE_LSI|RCC_OSCILLATORTYPE_HSE;
  RCC_OscInitStruct.HSEState = RCC_HSE_ON;
  RCC_OscInitStruct.LSIState = RCC_LSI_ON;
  RCC_OscInitStruct.PLL.PLLState = RCC_PLL_ON;
  RCC_OscInitStruct.PLL.PLLSource = RCC_PLLSOURCE_HSE;
  RCC_OscInitStruct.PLL.PLLM = 3;
  RCC_OscInitStruct.PLL.PLLN = 120;
  RCC_OscInitStruct.PLL.PLLP = 2;
  RCC_OscInitStruct.PLL.PLLQ = 20;
  RCC_OscInitStruct.PLL.PLLR = 2;
  RCC_OscInitStruct.PLL.PLLRGE = RCC_PLL1VCIRANGE_3;
  RCC_OscInitStruct.PLL.PLLVCOSEL = RCC_PLL1VCOWIDE;
  RCC_OscInitStruct.PLL.PLLFRACN = 0;
  if (HAL_RCC_OscConfig(&RCC_OscInitStruct) != HAL_OK)
  {
    Error_Handler();
  }

  /** Initializes the CPU, AHB and APB buses clocks
  */
  RCC_ClkInitStruct.ClockType = RCC_CLOCKTYPE_HCLK|RCC_CLOCKTYPE_SYSCLK
                              |RCC_CLOCKTYPE_PCLK1|RCC_CLOCKTYPE_PCLK2
                              |RCC_CLOCKTYPE_D3PCLK1|RCC_CLOCKTYPE_D1PCLK1;
  RCC_ClkInitStruct.SYSCLKSource = RCC_SYSCLKSOURCE_PLLCLK;
  RCC_ClkInitStruct.SYSCLKDivider = RCC_SYSCLK_DIV1;
  RCC_ClkInitStruct.AHBCLKDivider = RCC_HCLK_DIV2;
  RCC_ClkInitStruct.APB3CLKDivider = RCC_APB3_DIV2;
  RCC_ClkInitStruct.APB1CLKDivider = RCC_APB1_DIV2;
  RCC_ClkInitStruct.APB2CLKDivider = RCC_APB2_DIV2;
  RCC_ClkInitStruct.APB4CLKDivider = RCC_APB4_DIV2;

  if (HAL_RCC_ClockConfig(&RCC_ClkInitStruct, FLASH_LATENCY_4) != HAL_OK)
  {
    Error_Handler();
  }
  __HAL_RCC_PLL2CLKOUT_ENABLE(RCC_PLL2_DIVP);
  HAL_RCC_MCOConfig(RCC_MCO2, RCC_MCO2SOURCE_PLL2PCLK, RCC_MCODIV_5);
}

void PeriphCommonClock_Config(void)
{
  RCC_PeriphCLKInitTypeDef PeriphClkInitStruct = {0};

  /** Initializes the peripherals clock
  */
  PeriphClkInitStruct.PeriphClockSelection = RCC_PERIPHCLK_SPI3|RCC_PERIPHCLK_SPI2;
  PeriphClkInitStruct.PLL2.PLL2M = 6;
  PeriphClkInitStruct.PLL2.PLL2N = 120;
  PeriphClkInitStruct.PLL2.PLL2P = 4;
  PeriphClkInitStruct.PLL2.PLL2Q = 2;
  PeriphClkInitStruct.PLL2.PLL2R = 2;
  PeriphClkInitStruct.PLL2.PLL2RGE = RCC_PLL2VCIRANGE_2;
  PeriphClkInitStruct.PLL2.PLL2VCOSEL = RCC_PLL2VCOWIDE;
  PeriphClkInitStruct.PLL2.PLL2FRACN = 0;
  PeriphClkInitStruct.Spi123ClockSelection = RCC_SPI123CLKSOURCE_PLL2;
  if (HAL_RCCEx_PeriphCLKConfig(&PeriphClkInitStruct) != HAL_OK)
  {
    Error_Handler();
  }
}

static void MX_CRC_Init(void)
{

  hcrc.Instance = CRC;
  hcrc.Init.DefaultPolynomialUse = DEFAULT_POLYNOMIAL_ENABLE;
  hcrc.Init.DefaultInitValueUse = DEFAULT_INIT_VALUE_ENABLE;
  hcrc.Init.InputDataInversionMode = CRC_INPUTDATA_INVERSION_NONE;
  hcrc.Init.OutputDataInversionMode = CRC_OUTPUTDATA_INVERSION_DISABLE;
  hcrc.InputDataFormat = CRC_INPUTDATA_FORMAT_BYTES;
  if (HAL_CRC_Init(&hcrc) != HAL_OK)
  {
    Error_Handler();
  }

}

static void MX_I2C1_Init(void)
{

  hi2c1.Instance = I2C1;
  hi2c1.Init.Timing = 0x00B03FDB;
  hi2c1.Init.OwnAddress1 = 0;
  hi2c1.Init.AddressingMode = I2C_ADDRESSINGMODE_7BIT;
  hi2c1.Init.DualAddressMode = I2C_DUALADDRESS_DISABLE;
  hi2c1.Init.OwnAddress2 = 0;
  hi2c1.Init.OwnAddress2Masks = I2C_OA2_NOMASK;
  hi2c1.Init.GeneralCallMode = I2C_GENERALCALL_DISABLE;
  hi2c1.Init.NoStretchMode = I2C_NOSTRETCH_DISABLE;
  if (HAL_I2C_Init(&hi2c1) != HAL_OK)
  {
    Error_Handler();
  }

  /** Configure Analogue filter
  */
  if (HAL_I2CEx_ConfigAnalogFilter(&hi2c1, I2C_ANALOGFILTER_ENABLE) != HAL_OK)
  {
    Error_Handler();
  }

  /** Configure Digital filter
  */
  if (HAL_I2CEx_ConfigDigitalFilter(&hi2c1, 0) != HAL_OK)
  {
    Error_Handler();
  }

}

static void MX_IWDG1_Init(void)
{

  /* USER CODE BEGIN IWDG1_Init 1 */
  /* 250 ms window (#136): LSI 32 kHz / 64 = 500 Hz, reload 124 -> 125 ticks.
   * The LSI is specified at 29.76-33.6 kHz, so the real window is 238-269 ms.
   * Every main-loop iteration has to finish inside the short end of that. */
  /* USER CODE END IWDG1_Init 1 */
  hiwdg1.Instance = IWDG1;
  hiwdg1.Init.Prescaler = IWDG_PRESCALER_64;
  hiwdg1.Init.Window = 4095;
  hiwdg1.Init.Reload = 124;
  if (HAL_IWDG_Init(&hiwdg1) != HAL_OK)
  {
    Error_Handler();
  }

}

static void MX_RAMECC_Init(void)
{

  /** Initialize RAMECC1 M1 : AXI SRAM
  */
  hramecc1_m1.Instance = RAMECC1_Monitor1;
  if (HAL_RAMECC_Init(&hramecc1_m1) != HAL_OK)
  {
    Error_Handler();
  }

  /** Initialize RAMECC1 M2 : ITCM-RAM
  */
  hramecc1_m2.Instance = RAMECC1_Monitor2;
  if (HAL_RAMECC_Init(&hramecc1_m2) != HAL_OK)
  {
    Error_Handler();
  }

  /** Initialize RAMECC1 M3 : D0TCM-RAM
  */
  hramecc1_m3.Instance = RAMECC1_Monitor3;
  if (HAL_RAMECC_Init(&hramecc1_m3) != HAL_OK)
  {
    Error_Handler();
  }

  /** Initialize RAMECC1 M4 : D1TCM-RAM
  */
  hramecc1_m4.Instance = RAMECC1_Monitor4;
  if (HAL_RAMECC_Init(&hramecc1_m4) != HAL_OK)
  {
    Error_Handler();
  }

  /** Initialize RAMECC1 M5 : ETM RAM
  */
  hramecc1_m5.Instance = RAMECC1_Monitor5;
  if (HAL_RAMECC_Init(&hramecc1_m5) != HAL_OK)
  {
    Error_Handler();
  }

  /** Initialize RAMECC2 M1 : SRAM1_0
  */
  hramecc2_m1.Instance = RAMECC2_Monitor1;
  if (HAL_RAMECC_Init(&hramecc2_m1) != HAL_OK)
  {
    Error_Handler();
  }

  /** Initialize RAMECC2 M2 SRAM1_1
  */
  hramecc2_m2.Instance = RAMECC2_Monitor2;
  if (HAL_RAMECC_Init(&hramecc2_m2) != HAL_OK)
  {
    Error_Handler();
  }

  /** Initialize RAMECC2 M3 : SRAM2_0
  */
  hramecc2_m3.Instance = RAMECC2_Monitor3;
  if (HAL_RAMECC_Init(&hramecc2_m3) != HAL_OK)
  {
    Error_Handler();
  }

  /** Initialize RAMECC2 M4 : SRAM2_1
  */
  hramecc2_m4.Instance = RAMECC2_Monitor4;
  if (HAL_RAMECC_Init(&hramecc2_m4) != HAL_OK)
  {
    Error_Handler();
  }

  /** Initialize RAMECC2 M5 : SRAM3
  */
  hramecc2_m5.Instance = RAMECC2_Monitor5;
  if (HAL_RAMECC_Init(&hramecc2_m5) != HAL_OK)
  {
    Error_Handler();
  }

  /** Initialize RAMECC3 M1 : SRAM4
  */
  hramecc3_m1.Instance = RAMECC3_Monitor1;
  if (HAL_RAMECC_Init(&hramecc3_m1) != HAL_OK)
  {
    Error_Handler();
  }

  /** Initialize RAMECC3 M2 : Backup RAM
  */
  hramecc3_m2.Instance = RAMECC3_Monitor2;
  if (HAL_RAMECC_Init(&hramecc3_m2) != HAL_OK)
  {
    Error_Handler();
  }

}

static void MX_RNG_Init(void)
{

  hrng.Instance = RNG;
  hrng.Init.ClockErrorDetection = RNG_CED_ENABLE;
  if (HAL_RNG_Init(&hrng) != HAL_OK)
  {
    Error_Handler();
  }

}

static void MX_SPI2_Init(void)
{

  /* SPI2 parameter configuration*/
  hspi2.Instance = SPI2;
  hspi2.Init.Mode = SPI_MODE_SLAVE;
  hspi2.Init.Direction = SPI_DIRECTION_2LINES;
  hspi2.Init.DataSize = SPI_DATASIZE_8BIT;
  hspi2.Init.CLKPolarity = SPI_POLARITY_HIGH;
  hspi2.Init.CLKPhase = SPI_PHASE_2EDGE;
  hspi2.Init.NSS = SPI_NSS_SOFT;
  hspi2.Init.FirstBit = SPI_FIRSTBIT_LSB;
  hspi2.Init.TIMode = SPI_TIMODE_DISABLE;
  hspi2.Init.CRCCalculation = SPI_CRCCALCULATION_DISABLE;
  hspi2.Init.CRCPolynomial = 0x0;
  hspi2.Init.NSSPMode = SPI_NSS_PULSE_DISABLE;
  hspi2.Init.NSSPolarity = SPI_NSS_POLARITY_LOW;
  hspi2.Init.FifoThreshold = SPI_FIFO_THRESHOLD_01DATA;
  hspi2.Init.TxCRCInitializationPattern = SPI_CRC_INITIALIZATION_ALL_ZERO_PATTERN;
  hspi2.Init.RxCRCInitializationPattern = SPI_CRC_INITIALIZATION_ALL_ZERO_PATTERN;
  hspi2.Init.MasterSSIdleness = SPI_MASTER_SS_IDLENESS_00CYCLE;
  hspi2.Init.MasterInterDataIdleness = SPI_MASTER_INTERDATA_IDLENESS_00CYCLE;
  hspi2.Init.MasterReceiverAutoSusp = SPI_MASTER_RX_AUTOSUSP_DISABLE;
  hspi2.Init.MasterKeepIOState = SPI_MASTER_KEEP_IO_STATE_DISABLE;
  hspi2.Init.IOSwap = SPI_IO_SWAP_DISABLE;
  if (HAL_SPI_Init(&hspi2) != HAL_OK)
  {
    Error_Handler();
  }

}

static void MX_SPI3_Init(void)
{

  /* SPI3 parameter configuration*/
  hspi3.Instance = SPI3;
  hspi3.Init.Mode = SPI_MODE_SLAVE;
  hspi3.Init.Direction = SPI_DIRECTION_2LINES;
  hspi3.Init.DataSize = SPI_DATASIZE_8BIT;
  hspi3.Init.CLKPolarity = SPI_POLARITY_HIGH;
  hspi3.Init.CLKPhase = SPI_PHASE_2EDGE;
  hspi3.Init.NSS = SPI_NSS_SOFT;
  hspi3.Init.FirstBit = SPI_FIRSTBIT_LSB;
  hspi3.Init.TIMode = SPI_TIMODE_DISABLE;
  hspi3.Init.CRCCalculation = SPI_CRCCALCULATION_DISABLE;
  hspi3.Init.CRCPolynomial = 0x0;
  hspi3.Init.NSSPMode = SPI_NSS_PULSE_DISABLE;
  hspi3.Init.NSSPolarity = SPI_NSS_POLARITY_LOW;
  hspi3.Init.FifoThreshold = SPI_FIFO_THRESHOLD_01DATA;
  hspi3.Init.TxCRCInitializationPattern = SPI_CRC_INITIALIZATION_ALL_ZERO_PATTERN;
  hspi3.Init.RxCRCInitializationPattern = SPI_CRC_INITIALIZATION_ALL_ZERO_PATTERN;
  hspi3.Init.MasterSSIdleness = SPI_MASTER_SS_IDLENESS_00CYCLE;
  hspi3.Init.MasterInterDataIdleness = SPI_MASTER_INTERDATA_IDLENESS_00CYCLE;
  hspi3.Init.MasterReceiverAutoSusp = SPI_MASTER_RX_AUTOSUSP_DISABLE;
  hspi3.Init.MasterKeepIOState = SPI_MASTER_KEEP_IO_STATE_DISABLE;
  hspi3.Init.IOSwap = SPI_IO_SWAP_DISABLE;
  if (HAL_SPI_Init(&hspi3) != HAL_OK)
  {
    Error_Handler();
  }

}

static void MX_SPI4_Init(void)
{

  /* SPI4 parameter configuration*/
  hspi4.Instance = SPI4;
  hspi4.Init.Mode = SPI_MODE_SLAVE;
  hspi4.Init.Direction = SPI_DIRECTION_2LINES;
  hspi4.Init.DataSize = SPI_DATASIZE_8BIT;
  hspi4.Init.CLKPolarity = SPI_POLARITY_HIGH;
  hspi4.Init.CLKPhase = SPI_PHASE_2EDGE;
  hspi4.Init.NSS = SPI_NSS_SOFT;
  hspi4.Init.FirstBit = SPI_FIRSTBIT_LSB;
  hspi4.Init.TIMode = SPI_TIMODE_DISABLE;
  hspi4.Init.CRCCalculation = SPI_CRCCALCULATION_DISABLE;
  hspi4.Init.CRCPolynomial = 0x0;
  hspi4.Init.NSSPMode = SPI_NSS_PULSE_DISABLE;
  hspi4.Init.NSSPolarity = SPI_NSS_POLARITY_LOW;
  hspi4.Init.FifoThreshold = SPI_FIFO_THRESHOLD_01DATA;
  hspi4.Init.TxCRCInitializationPattern = SPI_CRC_INITIALIZATION_ALL_ZERO_PATTERN;
  hspi4.Init.RxCRCInitializationPattern = SPI_CRC_INITIALIZATION_ALL_ZERO_PATTERN;
  hspi4.Init.MasterSSIdleness = SPI_MASTER_SS_IDLENESS_00CYCLE;
  hspi4.Init.MasterInterDataIdleness = SPI_MASTER_INTERDATA_IDLENESS_00CYCLE;
  hspi4.Init.MasterReceiverAutoSusp = SPI_MASTER_RX_AUTOSUSP_DISABLE;
  hspi4.Init.MasterKeepIOState = SPI_MASTER_KEEP_IO_STATE_DISABLE;
  hspi4.Init.IOSwap = SPI_IO_SWAP_DISABLE;
  if (HAL_SPI_Init(&hspi4) != HAL_OK)
  {
    Error_Handler();
  }

}

static void MX_SPI6_Init(void)
{

  /* SPI6 parameter configuration*/
  hspi6.Instance = SPI6;
  hspi6.Init.Mode = SPI_MODE_SLAVE;
  hspi6.Init.Direction = SPI_DIRECTION_2LINES;
  hspi6.Init.DataSize = SPI_DATASIZE_8BIT;
  hspi6.Init.CLKPolarity = SPI_POLARITY_HIGH;
  hspi6.Init.CLKPhase = SPI_PHASE_2EDGE;
  hspi6.Init.NSS = SPI_NSS_SOFT;
  hspi6.Init.FirstBit = SPI_FIRSTBIT_LSB;
  hspi6.Init.TIMode = SPI_TIMODE_DISABLE;
  hspi6.Init.CRCCalculation = SPI_CRCCALCULATION_DISABLE;
  hspi6.Init.CRCPolynomial = 0x0;
  hspi6.Init.NSSPMode = SPI_NSS_PULSE_DISABLE;
  hspi6.Init.NSSPolarity = SPI_NSS_POLARITY_LOW;
  hspi6.Init.FifoThreshold = SPI_FIFO_THRESHOLD_01DATA;
  hspi6.Init.TxCRCInitializationPattern = SPI_CRC_INITIALIZATION_ALL_ZERO_PATTERN;
  hspi6.Init.RxCRCInitializationPattern = SPI_CRC_INITIALIZATION_ALL_ZERO_PATTERN;
  hspi6.Init.MasterSSIdleness = SPI_MASTER_SS_IDLENESS_00CYCLE;
  hspi6.Init.MasterInterDataIdleness = SPI_MASTER_INTERDATA_IDLENESS_00CYCLE;
  hspi6.Init.MasterReceiverAutoSusp = SPI_MASTER_RX_AUTOSUSP_DISABLE;
  hspi6.Init.MasterKeepIOState = SPI_MASTER_KEEP_IO_STATE_DISABLE;
  hspi6.Init.IOSwap = SPI_IO_SWAP_DISABLE;
  if (HAL_SPI_Init(&hspi6) != HAL_OK)
  {
    Error_Handler();
  }

}

static void MX_TIM2_Init(void)
{

  TIM_ClockConfigTypeDef sClockSourceConfig = {0};
  TIM_MasterConfigTypeDef sMasterConfig = {0};
  TIM_OC_InitTypeDef sConfigOC = {0};

  htim2.Instance = TIM2;
  htim2.Init.Prescaler = 0;
  htim2.Init.CounterMode = TIM_COUNTERMODE_UP;
  htim2.Init.Period = 4294967295;
  htim2.Init.ClockDivision = TIM_CLOCKDIVISION_DIV1;
  htim2.Init.AutoReloadPreload = TIM_AUTORELOAD_PRELOAD_DISABLE;
  if (HAL_TIM_Base_Init(&htim2) != HAL_OK)
  {
    Error_Handler();
  }
  sClockSourceConfig.ClockSource = TIM_CLOCKSOURCE_INTERNAL;
  if (HAL_TIM_ConfigClockSource(&htim2, &sClockSourceConfig) != HAL_OK)
  {
    Error_Handler();
  }
  if (HAL_TIM_PWM_Init(&htim2) != HAL_OK)
  {
    Error_Handler();
  }
  sMasterConfig.MasterOutputTrigger = TIM_TRGO_RESET;
  sMasterConfig.MasterSlaveMode = TIM_MASTERSLAVEMODE_DISABLE;
  if (HAL_TIMEx_MasterConfigSynchronization(&htim2, &sMasterConfig) != HAL_OK)
  {
    Error_Handler();
  }
  sConfigOC.OCMode = TIM_OCMODE_PWM1;
  sConfigOC.Pulse = 0;
  sConfigOC.OCPolarity = TIM_OCPOLARITY_HIGH;
  sConfigOC.OCFastMode = TIM_OCFAST_DISABLE;
  if (HAL_TIM_PWM_ConfigChannel(&htim2, &sConfigOC, TIM_CHANNEL_2) != HAL_OK)
  {
    Error_Handler();
  }
  HAL_TIM_MspPostInit(&htim2);

}

static void MX_TIM4_Init(void)
{

  TIM_MasterConfigTypeDef sMasterConfig = {0};
  TIM_OC_InitTypeDef sConfigOC = {0};

  htim4.Instance = TIM4;
  htim4.Init.Prescaler = 1000;
  htim4.Init.CounterMode = TIM_COUNTERMODE_UP;
  htim4.Init.Period = 5999;
  htim4.Init.ClockDivision = TIM_CLOCKDIVISION_DIV1;
  htim4.Init.AutoReloadPreload = TIM_AUTORELOAD_PRELOAD_DISABLE;
  if (HAL_TIM_PWM_Init(&htim4) != HAL_OK)
  {
    Error_Handler();
  }
  if (HAL_TIM_OC_Init(&htim4) != HAL_OK)
  {
    Error_Handler();
  }
  sMasterConfig.MasterOutputTrigger = TIM_TRGO_RESET;
  sMasterConfig.MasterSlaveMode = TIM_MASTERSLAVEMODE_DISABLE;
  if (HAL_TIMEx_MasterConfigSynchronization(&htim4, &sMasterConfig) != HAL_OK)
  {
    Error_Handler();
  }
  sConfigOC.OCMode = TIM_OCMODE_PWM1;
  sConfigOC.Pulse = 3000;
  sConfigOC.OCPolarity = TIM_OCPOLARITY_LOW;
  sConfigOC.OCFastMode = TIM_OCFAST_DISABLE;
  if (HAL_TIM_PWM_ConfigChannel(&htim4, &sConfigOC, TIM_CHANNEL_2) != HAL_OK)
  {
    Error_Handler();
  }
  sConfigOC.OCMode = TIM_OCMODE_TIMING;
  sConfigOC.OCPolarity = TIM_OCPOLARITY_HIGH;
  if (HAL_TIM_OC_ConfigChannel(&htim4, &sConfigOC, TIM_CHANNEL_3) != HAL_OK)
  {
    Error_Handler();
  }
  /* USER CODE BEGIN TIM4_Init 2 */
  LL_TIM_EnableIT_CC1(TIM4);
  /* USER CODE END TIM4_Init 2 */
  HAL_TIM_MspPostInit(&htim4);

}

static void MX_TIM5_Init(void)
{

  TIM_ClockConfigTypeDef sClockSourceConfig = {0};
  TIM_MasterConfigTypeDef sMasterConfig = {0};

  htim5.Instance = TIM5;
  htim5.Init.Prescaler = 2400-1;
  htim5.Init.CounterMode = TIM_COUNTERMODE_UP;
  htim5.Init.Period = 0xFFFFFFFF;
  htim5.Init.ClockDivision = TIM_CLOCKDIVISION_DIV1;
  htim5.Init.AutoReloadPreload = TIM_AUTORELOAD_PRELOAD_DISABLE;
  if (HAL_TIM_Base_Init(&htim5) != HAL_OK)
  {
    Error_Handler();
  }
  sClockSourceConfig.ClockSource = TIM_CLOCKSOURCE_INTERNAL;
  if (HAL_TIM_ConfigClockSource(&htim5, &sClockSourceConfig) != HAL_OK)
  {
    Error_Handler();
  }
  sMasterConfig.MasterOutputTrigger = TIM_TRGO_RESET;
  sMasterConfig.MasterSlaveMode = TIM_MASTERSLAVEMODE_DISABLE;
  if (HAL_TIMEx_MasterConfigSynchronization(&htim5, &sMasterConfig) != HAL_OK)
  {
    Error_Handler();
  }

}

static void MX_TIM8_Init(void)
{

  TIM_ClockConfigTypeDef sClockSourceConfig = {0};
  TIM_MasterConfigTypeDef sMasterConfig = {0};

  htim8.Instance = TIM8;
  htim8.Init.Prescaler = 0;
  htim8.Init.CounterMode = TIM_COUNTERMODE_UP;
  htim8.Init.Period = 10-1;
  htim8.Init.ClockDivision = TIM_CLOCKDIVISION_DIV1;
  htim8.Init.RepetitionCounter = 0;
  htim8.Init.AutoReloadPreload = TIM_AUTORELOAD_PRELOAD_DISABLE;
  if (HAL_TIM_Base_Init(&htim8) != HAL_OK)
  {
    Error_Handler();
  }
  sClockSourceConfig.ClockSource = TIM_CLOCKSOURCE_INTERNAL;
  if (HAL_TIM_ConfigClockSource(&htim8, &sClockSourceConfig) != HAL_OK)
  {
    Error_Handler();
  }
  sMasterConfig.MasterOutputTrigger = TIM_TRGO_RESET;
  sMasterConfig.MasterOutputTrigger2 = TIM_TRGO2_RESET;
  sMasterConfig.MasterSlaveMode = TIM_MASTERSLAVEMODE_DISABLE;
  if (HAL_TIMEx_MasterConfigSynchronization(&htim8, &sMasterConfig) != HAL_OK)
  {
    Error_Handler();
  }

}

static void MX_TIM14_Init(void)
{

  htim14.Instance = TIM14;
  htim14.Init.Prescaler = 240-1;
  htim14.Init.CounterMode = TIM_COUNTERMODE_UP;
  htim14.Init.Period = 25000-1;
  htim14.Init.ClockDivision = TIM_CLOCKDIVISION_DIV1;
  htim14.Init.AutoReloadPreload = TIM_AUTORELOAD_PRELOAD_DISABLE;
  if (HAL_TIM_Base_Init(&htim14) != HAL_OK)
  {
    Error_Handler();
  }

}

static void MX_TIM15_Init(void)
{

  TIM_ClockConfigTypeDef sClockSourceConfig = {0};
  TIM_MasterConfigTypeDef sMasterConfig = {0};

  htim15.Instance = TIM15;
  htim15.Init.Prescaler = 240-1;
  htim15.Init.CounterMode = TIM_COUNTERMODE_UP;
  htim15.Init.Period = 65535;
  htim15.Init.ClockDivision = TIM_CLOCKDIVISION_DIV1;
  htim15.Init.RepetitionCounter = 0;
  htim15.Init.AutoReloadPreload = TIM_AUTORELOAD_PRELOAD_DISABLE;
  if (HAL_TIM_Base_Init(&htim15) != HAL_OK)
  {
    Error_Handler();
  }
  sClockSourceConfig.ClockSource = TIM_CLOCKSOURCE_INTERNAL;
  if (HAL_TIM_ConfigClockSource(&htim15, &sClockSourceConfig) != HAL_OK)
  {
    Error_Handler();
  }
  sMasterConfig.MasterOutputTrigger = TIM_TRGO_RESET;
  sMasterConfig.MasterSlaveMode = TIM_MASTERSLAVEMODE_DISABLE;
  if (HAL_TIMEx_MasterConfigSynchronization(&htim15, &sMasterConfig) != HAL_OK)
  {
    Error_Handler();
  }

}

static void MX_TIM16_Init(void)
{

  htim16.Instance = TIM16;
  htim16.Init.Prescaler = 240-1;
  htim16.Init.CounterMode = TIM_COUNTERMODE_UP;
  htim16.Init.Period = 25000-1;
  htim16.Init.ClockDivision = TIM_CLOCKDIVISION_DIV1;
  htim16.Init.RepetitionCounter = 0;
  htim16.Init.AutoReloadPreload = TIM_AUTORELOAD_PRELOAD_DISABLE;
  if (HAL_TIM_Base_Init(&htim16) != HAL_OK)
  {
    Error_Handler();
  }

}

static void MX_UART4_Init(void)
{

  huart4.Instance = UART4;
  huart4.Init.BaudRate = 115200;
  huart4.Init.WordLength = UART_WORDLENGTH_8B;
  huart4.Init.StopBits = UART_STOPBITS_1;
  huart4.Init.Parity = UART_PARITY_NONE;
  huart4.Init.Mode = UART_MODE_TX_RX;
  huart4.Init.HwFlowCtl = UART_HWCONTROL_NONE;
  huart4.Init.OverSampling = UART_OVERSAMPLING_16;
  huart4.Init.OneBitSampling = UART_ONE_BIT_SAMPLE_DISABLE;
  huart4.Init.ClockPrescaler = UART_PRESCALER_DIV1;
  huart4.AdvancedInit.AdvFeatureInit = UART_ADVFEATURE_NO_INIT;
  if (HAL_UART_Init(&huart4) != HAL_OK)
  {
    Error_Handler();
  }
  if (HAL_UARTEx_SetTxFifoThreshold(&huart4, UART_TXFIFO_THRESHOLD_1_8) != HAL_OK)
  {
    Error_Handler();
  }
  if (HAL_UARTEx_SetRxFifoThreshold(&huart4, UART_RXFIFO_THRESHOLD_1_8) != HAL_OK)
  {
    Error_Handler();
  }
  if (HAL_UARTEx_DisableFifoMode(&huart4) != HAL_OK)
  {
    Error_Handler();
  }

}

static void MX_USART1_Init(void)
{

  husart1.Instance = USART1;
  husart1.Init.BaudRate = 115200;
  husart1.Init.WordLength = USART_WORDLENGTH_8B;
  husart1.Init.StopBits = USART_STOPBITS_1;
  husart1.Init.Parity = USART_PARITY_NONE;
  husart1.Init.Mode = USART_MODE_RX;
  husart1.Init.CLKPolarity = USART_POLARITY_HIGH;
  husart1.Init.CLKPhase = USART_PHASE_2EDGE;
  husart1.Init.CLKLastBit = USART_LASTBIT_DISABLE;
  husart1.Init.ClockPrescaler = USART_PRESCALER_DIV1;
  husart1.SlaveMode = USART_SLAVEMODE_ENABLE;
  if (HAL_USART_Init(&husart1) != HAL_OK)
  {
    Error_Handler();
  }
  if (HAL_USARTEx_SetTxFifoThreshold(&husart1, USART_TXFIFO_THRESHOLD_1_8) != HAL_OK)
  {
    Error_Handler();
  }
  if (HAL_USARTEx_SetRxFifoThreshold(&husart1, USART_RXFIFO_THRESHOLD_8_8) != HAL_OK)
  {
    Error_Handler();
  }
  if (HAL_USARTEx_EnableFifoMode(&husart1) != HAL_OK)
  {
    Error_Handler();
  }
  if (HAL_USARTEx_EnableSlaveMode(&husart1) != HAL_OK)
  {
    Error_Handler();
  }

}

static void MX_USART2_Init(void)
{

  husart2.Instance = USART2;
  husart2.Init.BaudRate = 5000000;
  husart2.Init.WordLength = USART_WORDLENGTH_8B;
  husart2.Init.StopBits = USART_STOPBITS_1;
  husart2.Init.Parity = USART_PARITY_NONE;
  husart2.Init.Mode = USART_MODE_RX;
  husart2.Init.CLKPolarity = USART_POLARITY_HIGH;
  husart2.Init.CLKPhase = USART_PHASE_2EDGE;
  husart2.Init.CLKLastBit = USART_LASTBIT_DISABLE;
  husart2.Init.ClockPrescaler = USART_PRESCALER_DIV1;
  husart2.SlaveMode = USART_SLAVEMODE_ENABLE;
  if (HAL_USART_Init(&husart2) != HAL_OK)
  {
    Error_Handler();
  }
  if (HAL_USARTEx_SetTxFifoThreshold(&husart2, USART_TXFIFO_THRESHOLD_1_8) != HAL_OK)
  {
    Error_Handler();
  }
  if (HAL_USARTEx_SetRxFifoThreshold(&husart2, USART_RXFIFO_THRESHOLD_8_8) != HAL_OK)
  {
    Error_Handler();
  }
  if (HAL_USARTEx_EnableFifoMode(&husart2) != HAL_OK)
  {
    Error_Handler();
  }
  if (HAL_USARTEx_EnableSlaveMode(&husart2) != HAL_OK)
  {
    Error_Handler();
  }

}

static void MX_USART3_Init(void)
{

  husart3.Instance = USART3;
  husart3.Init.BaudRate = 115200;
  husart3.Init.WordLength = USART_WORDLENGTH_8B;
  husart3.Init.StopBits = USART_STOPBITS_1;
  husart3.Init.Parity = USART_PARITY_NONE;
  husart3.Init.Mode = USART_MODE_RX;
  husart3.Init.CLKPolarity = USART_POLARITY_HIGH;
  husart3.Init.CLKPhase = USART_PHASE_2EDGE;
  husart3.Init.CLKLastBit = USART_LASTBIT_DISABLE;
  husart3.Init.ClockPrescaler = USART_PRESCALER_DIV1;
  husart3.SlaveMode = USART_SLAVEMODE_ENABLE;
  if (HAL_USART_Init(&husart3) != HAL_OK)
  {
    Error_Handler();
  }
  if (HAL_USARTEx_SetTxFifoThreshold(&husart3, USART_TXFIFO_THRESHOLD_1_8) != HAL_OK)
  {
    Error_Handler();
  }
  if (HAL_USARTEx_SetRxFifoThreshold(&husart3, USART_RXFIFO_THRESHOLD_8_8) != HAL_OK)
  {
    Error_Handler();
  }
  if (HAL_USARTEx_EnableFifoMode(&husart3) != HAL_OK)
  {
    Error_Handler();
  }
  if (HAL_USARTEx_EnableSlaveMode(&husart3) != HAL_OK)
  {
    Error_Handler();
  }

}

static void MX_USART6_Init(void)
{

  husart6.Instance = USART6;
  husart6.Init.BaudRate = 4167000;
  husart6.Init.WordLength = USART_WORDLENGTH_8B;
  husart6.Init.StopBits = USART_STOPBITS_1;
  husart6.Init.Parity = USART_PARITY_NONE;
  husart6.Init.Mode = USART_MODE_RX;
  husart6.Init.CLKPolarity = USART_POLARITY_HIGH;
  husart6.Init.CLKPhase = USART_PHASE_2EDGE;
  husart6.Init.CLKLastBit = USART_LASTBIT_DISABLE;
  husart6.Init.ClockPrescaler = USART_PRESCALER_DIV1;
  husart6.SlaveMode = USART_SLAVEMODE_ENABLE;
  if (HAL_USART_Init(&husart6) != HAL_OK)
  {
    Error_Handler();
  }
  if (HAL_USARTEx_SetTxFifoThreshold(&husart6, USART_TXFIFO_THRESHOLD_1_8) != HAL_OK)
  {
    Error_Handler();
  }
  if (HAL_USARTEx_SetRxFifoThreshold(&husart6, USART_RXFIFO_THRESHOLD_8_8) != HAL_OK)
  {
    Error_Handler();
  }
  if (HAL_USARTEx_EnableFifoMode(&husart6) != HAL_OK)
  {
    Error_Handler();
  }
  if (HAL_USARTEx_EnableSlaveMode(&husart6) != HAL_OK)
  {
    Error_Handler();
  }

}

static void MX_BDMA_Init(void)
{

  /* DMA controller clock enable */
  __HAL_RCC_BDMA_CLK_ENABLE();

  /* DMA interrupt init */
  /* BDMA_Channel0_IRQn interrupt configuration */
  HAL_NVIC_SetPriority(BDMA_Channel0_IRQn, DMA_IRQ_PRIORITY, 0);
  HAL_NVIC_EnableIRQ(BDMA_Channel0_IRQn);

}

static void MX_DMA_Init(void)
{

  /* DMA controller clock enable */
  __HAL_RCC_DMA1_CLK_ENABLE();
  __HAL_RCC_DMA2_CLK_ENABLE();

  /* Configure DMA request hdma_memtomem_dma2_stream1 on DMA2_Stream1 */
  hdma_memtomem_dma2_stream1.Instance = DMA2_Stream1;
  hdma_memtomem_dma2_stream1.Init.Request = DMA_REQUEST_MEM2MEM;
  hdma_memtomem_dma2_stream1.Init.Direction = DMA_MEMORY_TO_MEMORY;
  hdma_memtomem_dma2_stream1.Init.PeriphInc = DMA_PINC_DISABLE;
  hdma_memtomem_dma2_stream1.Init.MemInc = DMA_MINC_ENABLE;
  hdma_memtomem_dma2_stream1.Init.PeriphDataAlignment = DMA_PDATAALIGN_WORD;
  hdma_memtomem_dma2_stream1.Init.MemDataAlignment = DMA_MDATAALIGN_WORD;
  hdma_memtomem_dma2_stream1.Init.Mode = DMA_NORMAL;
  hdma_memtomem_dma2_stream1.Init.Priority = DMA_PRIORITY_MEDIUM;
  hdma_memtomem_dma2_stream1.Init.FIFOMode = DMA_FIFOMODE_ENABLE;
  hdma_memtomem_dma2_stream1.Init.FIFOThreshold = DMA_FIFO_THRESHOLD_FULL;
  hdma_memtomem_dma2_stream1.Init.MemBurst = DMA_MBURST_INC4;
  hdma_memtomem_dma2_stream1.Init.PeriphBurst = DMA_PBURST_INC4;
  if (HAL_DMA_Init(&hdma_memtomem_dma2_stream1) != HAL_OK)
  {
    Error_Handler( );
  }

  /* DMA interrupt init */
  /* #116: DMA1_Stream2-7 + DMA2_Stream0 carry camera RX completions (SPI2/3/4
   * RX, USART2/1/3/6 RX) — CAMERA_RX_IRQ_PRIORITY tier, see common.h.
   * DMA1_Stream0/1 are UART4 logging RX/TX and stay at 0 (short ISRs). */
  /* DMA1_Stream0_IRQn interrupt configuration */
  HAL_NVIC_SetPriority(DMA1_Stream0_IRQn, 0, 0);
  HAL_NVIC_EnableIRQ(DMA1_Stream0_IRQn);
  /* DMA1_Stream1_IRQn interrupt configuration */
  HAL_NVIC_SetPriority(DMA1_Stream1_IRQn, 0, 0);
  HAL_NVIC_EnableIRQ(DMA1_Stream1_IRQn);
  /* DMA1_Stream2_IRQn interrupt configuration */
  HAL_NVIC_SetPriority(DMA1_Stream2_IRQn, CAMERA_RX_IRQ_PRIORITY, 0);
  HAL_NVIC_EnableIRQ(DMA1_Stream2_IRQn);
  /* DMA1_Stream3_IRQn interrupt configuration */
  HAL_NVIC_SetPriority(DMA1_Stream3_IRQn, CAMERA_RX_IRQ_PRIORITY, 0);
  HAL_NVIC_EnableIRQ(DMA1_Stream3_IRQn);
  /* DMA1_Stream4_IRQn interrupt configuration */
  HAL_NVIC_SetPriority(DMA1_Stream4_IRQn, CAMERA_RX_IRQ_PRIORITY, 0);
  HAL_NVIC_EnableIRQ(DMA1_Stream4_IRQn);
  /* DMA1_Stream5_IRQn interrupt configuration */
  HAL_NVIC_SetPriority(DMA1_Stream5_IRQn, CAMERA_RX_IRQ_PRIORITY, 0);
  HAL_NVIC_EnableIRQ(DMA1_Stream5_IRQn);
  /* DMA1_Stream6_IRQn interrupt configuration */
  HAL_NVIC_SetPriority(DMA1_Stream6_IRQn, CAMERA_RX_IRQ_PRIORITY, 0);
  HAL_NVIC_EnableIRQ(DMA1_Stream6_IRQn);
  /* DMA1_Stream7_IRQn interrupt configuration */
  HAL_NVIC_SetPriority(DMA1_Stream7_IRQn, CAMERA_RX_IRQ_PRIORITY, 0);
  HAL_NVIC_EnableIRQ(DMA1_Stream7_IRQn);
  /* DMA2_Stream0_IRQn interrupt configuration */
  HAL_NVIC_SetPriority(DMA2_Stream0_IRQn, CAMERA_RX_IRQ_PRIORITY, 0);
  HAL_NVIC_EnableIRQ(DMA2_Stream0_IRQn);

}

static void MX_GPIO_Init(void)
{
  GPIO_InitTypeDef GPIO_InitStruct = {0};

  /* GPIO Ports Clock Enable */
  __HAL_RCC_GPIOC_CLK_ENABLE();
  __HAL_RCC_GPIOE_CLK_ENABLE();
  __HAL_RCC_GPIOB_CLK_ENABLE();
  __HAL_RCC_GPIOA_CLK_ENABLE();
  __HAL_RCC_GPIOD_CLK_ENABLE();
  __HAL_RCC_GPIOH_CLK_ENABLE();

  /*Configure GPIO pin Output Level */
  HAL_GPIO_WritePin(GPIOC, ERROR_LED_Pin|MUX_RESET_Pin|USB_MUX_Pin, GPIO_PIN_RESET);

  /*Configure GPIO pin Output Level */
  HAL_GPIO_WritePin(USB_RESET_GPIO_Port, USB_RESET_Pin, GPIO_PIN_RESET);

  /*Configure GPIO pin Output Level */
  HAL_GPIO_WritePin(GPIOD, CAM_PWR_1_Pin|CAM_PWR_5_Pin|CAM_PWR_8_Pin|CAM_PWR_4_Pin
                          |FAN_CTL_Pin|FS_OUT_EN_Pin, GPIO_PIN_SET);

  /*Configure GPIO pin Output Level */
  HAL_GPIO_WritePin(GPIOE, CAM_PWR_7_Pin|CAM_PWR_2_Pin|FSIN_EN_Pin, GPIO_PIN_SET);

  /*Configure GPIO pin Output Level */
  HAL_GPIO_WritePin(CAM_PWR_3_GPIO_Port, CAM_PWR_3_Pin, GPIO_PIN_SET);

  /*Configure GPIO pin Output Level */
  HAL_GPIO_WritePin(CAM_PWR_6_GPIO_Port, CAM_PWR_6_Pin, GPIO_PIN_SET);

  /*Configure GPIO pins : ERROR_LED_Pin MUX_RESET_Pin USB_MUX_Pin CAM_PWR_6_Pin */
  GPIO_InitStruct.Pin = ERROR_LED_Pin|MUX_RESET_Pin|USB_MUX_Pin|CAM_PWR_6_Pin;
  GPIO_InitStruct.Mode = GPIO_MODE_OUTPUT_PP;
  GPIO_InitStruct.Pull = GPIO_NOPULL;
  GPIO_InitStruct.Speed = GPIO_SPEED_FREQ_LOW;
  HAL_GPIO_Init(GPIOC, &GPIO_InitStruct);

  /*Configure GPIO pins : GPIO0_8_Pin IMU_INT_Pin */
  GPIO_InitStruct.Pin = GPIO0_8_Pin|IMU_INT_Pin;
  GPIO_InitStruct.Mode = GPIO_MODE_ANALOG;
  GPIO_InitStruct.Pull = GPIO_NOPULL;
  HAL_GPIO_Init(GPIOC, &GPIO_InitStruct);

  /*Configure GPIO pins : GPIO0_7_Pin GPIO0_5_Pin */
  GPIO_InitStruct.Pin = GPIO0_7_Pin|GPIO0_5_Pin;
  GPIO_InitStruct.Mode = GPIO_MODE_ANALOG;
  GPIO_InitStruct.Pull = GPIO_NOPULL;
  HAL_GPIO_Init(GPIOB, &GPIO_InitStruct);

  /*Configure GPIO pins : USB_RESET_Pin CAM_PWR_3_Pin */
  GPIO_InitStruct.Pin = USB_RESET_Pin|CAM_PWR_3_Pin;
  GPIO_InitStruct.Mode = GPIO_MODE_OUTPUT_PP;
  GPIO_InitStruct.Pull = GPIO_NOPULL;
  GPIO_InitStruct.Speed = GPIO_SPEED_FREQ_LOW;
  HAL_GPIO_Init(GPIOA, &GPIO_InitStruct);

  /*Configure GPIO pins : GPIO0_6_Pin CRESET_8_Pin CRESET_7_Pin PE14
                           GPIO0_2_Pin GPIO0_3_Pin CRESET_1_Pin CRESET_3_Pin
                           CRESET_2_Pin CRESET_4_Pin */
  GPIO_InitStruct.Pin = GPIO0_6_Pin|CRESET_8_Pin|CRESET_7_Pin|GPIO_PIN_14
                          |GPIO0_2_Pin|GPIO0_3_Pin|CRESET_1_Pin|CRESET_3_Pin
                          |CRESET_2_Pin|CRESET_4_Pin;
  GPIO_InitStruct.Mode = GPIO_MODE_ANALOG;
  GPIO_InitStruct.Pull = GPIO_NOPULL;
  HAL_GPIO_Init(GPIOE, &GPIO_InitStruct);

  /*Configure GPIO pins : CRESET_6_Pin CRESET_5_Pin GPIO0_4_Pin */
  GPIO_InitStruct.Pin = CRESET_6_Pin|CRESET_5_Pin|GPIO0_4_Pin;
  GPIO_InitStruct.Mode = GPIO_MODE_ANALOG;
  GPIO_InitStruct.Pull = GPIO_NOPULL;
  HAL_GPIO_Init(GPIOD, &GPIO_InitStruct);

  /*Configure GPIO pins : CAM_PWR_1_Pin CAM_PWR_5_Pin CAM_PWR_8_Pin CAM_PWR_4_Pin
                           FAN_CTL_Pin FS_OUT_EN_Pin */
  GPIO_InitStruct.Pin = CAM_PWR_1_Pin|CAM_PWR_5_Pin|CAM_PWR_8_Pin|CAM_PWR_4_Pin
                          |FAN_CTL_Pin|FS_OUT_EN_Pin;
  GPIO_InitStruct.Mode = GPIO_MODE_OUTPUT_PP;
  GPIO_InitStruct.Pull = GPIO_NOPULL;
  GPIO_InitStruct.Speed = GPIO_SPEED_FREQ_LOW;
  HAL_GPIO_Init(GPIOD, &GPIO_InitStruct);

  /*Configure GPIO pins : PA12 PA11 */
  GPIO_InitStruct.Pin = GPIO_PIN_12|GPIO_PIN_11;
  GPIO_InitStruct.Mode = GPIO_MODE_AF_PP;
  GPIO_InitStruct.Pull = GPIO_NOPULL;
  GPIO_InitStruct.Speed = GPIO_SPEED_FREQ_LOW;
  GPIO_InitStruct.Alternate = GPIO_AF10_OTG1_FS;
  HAL_GPIO_Init(GPIOA, &GPIO_InitStruct);

  /*Configure GPIO pins : CAM_PWR_7_Pin CAM_PWR_2_Pin FSIN_EN_Pin */
  GPIO_InitStruct.Pin = CAM_PWR_7_Pin|CAM_PWR_2_Pin|FSIN_EN_Pin;
  GPIO_InitStruct.Mode = GPIO_MODE_OUTPUT_PP;
  GPIO_InitStruct.Pull = GPIO_NOPULL;
  GPIO_InitStruct.Speed = GPIO_SPEED_FREQ_LOW;
  HAL_GPIO_Init(GPIOE, &GPIO_InitStruct);

  /*Configure GPIO pin : PC9 */
  GPIO_InitStruct.Pin = GPIO_PIN_9;
  GPIO_InitStruct.Mode = GPIO_MODE_AF_PP;
  GPIO_InitStruct.Pull = GPIO_NOPULL;
  GPIO_InitStruct.Speed = GPIO_SPEED_FREQ_VERY_HIGH;
  GPIO_InitStruct.Alternate = GPIO_AF0_MCO;
  HAL_GPIO_Init(GPIOC, &GPIO_InitStruct);

  /*Configure GPIO pin : GPIO0_1_Pin */
  GPIO_InitStruct.Pin = GPIO0_1_Pin;
  GPIO_InitStruct.Mode = GPIO_MODE_ANALOG;
  GPIO_InitStruct.Pull = GPIO_NOPULL;
  HAL_GPIO_Init(GPIO0_1_GPIO_Port, &GPIO_InitStruct);

}

/* USER CODE BEGIN 4 */

// cppcheck-suppress constParameterPointer ; HAL weak callback signature is fixed by the STM32 HAL
void HAL_UART_RxCpltCallback(UART_HandleTypeDef *huart)
{
}

void HAL_UART_TxCpltCallback(UART_HandleTypeDef *huart)
{
  if (huart->Instance == UART4)
  {
    logging_UART_TxCpltCallback(huart);
  }
}

// Error handling callback for USART
void HAL_USART_ErrorCallback(USART_HandleTypeDef *husart)
{
  int8_t cam_id = -1;

  if (husart->Instance == USART1)
  {
    cam_id = 4;
  }
  else if (husart->Instance == USART2)
  {
    cam_id = 0;
  }
  else if (husart->Instance == USART3)
  {
    cam_id = 2;
  }
  else if (husart->Instance == USART6)
  {
    cam_id = 3;
  }

  // Print which USART instance caused the error
  if (husart->Instance == USART1)
  {
    printf("Error in USART1: ");
  }
  else if (husart->Instance == USART2)
  {
    printf("Error in USART2: ");
  }
  else if (husart->Instance == USART3)
  {
    printf("Error in USART3: ");
  }
  else if (husart->Instance == USART6)
  {
    printf("Error in USART6: ");
  }
  else
  {
    printf("Error in Unknown USART instance: ");
  }

  // Identify specific errors using error codes
  if (husart->ErrorCode & HAL_USART_ERROR_PE)
  {
    printf("Parity error ");
  }
  if (husart->ErrorCode & HAL_USART_ERROR_NE)
  {
    printf("Noise error ");
  }
  if (husart->ErrorCode & HAL_USART_ERROR_FE)
  {
    printf("Framing error ");
  }
  if (husart->ErrorCode & HAL_USART_ERROR_ORE)
  {
    printf("Overrun error ");
    __HAL_USART_CLEAR_OREFLAG(husart);
    if (cam_id >= 0) { cam_overrun_count[cam_id]++; }  /* #68 instrumentation */
  }
  if (husart->ErrorCode & HAL_USART_ERROR_DMA)
  {
    printf("DMA transfer error ");
  }
  printf("\r\n");

  /* Attempt graceful recovery for any known camera USART peripheral.
   * Same fix as HAL_SPI_ErrorCallback: non-overrun errors (framing, noise,
   * DMA) previously fell through to Error_Handler() and halted the MCU.
   * #116: recovery is now flag + PendSV re-arm instead of an in-ISR
   * abort_data_reception() (which busy-waited 10 ms in ISR context) +
   * one-shot start (which was terminal on failure). If the PendSV arm
   * fails, camera_rearm_service() retries from the main loop until it
   * sticks — a failed re-arm is no longer permanent. */
  if (cam_id >= 0)
  {
    camera_rx_error_recover((uint8_t)cam_id);
    return;
  }

  /* Truly unknown USART peripheral — log and continue rather than halting. */
  printf("[USART] Unhandled USART error on unknown peripheral, continuing.\r\n");
}

// Error handling callback for SPI
void HAL_SPI_ErrorCallback(SPI_HandleTypeDef *hspi)
{
  int8_t cam_id = -1;

  if (hspi->Instance == SPI2)
  {
    cam_id = 6;
  }
  else if (hspi->Instance == SPI3)
  {
    cam_id = 5;
  }
  else if (hspi->Instance == SPI4)
  {
    cam_id = 7;
  }
  else if (hspi->Instance == SPI6)
  {
    cam_id = 1;
  }

  // Print which SPI instance caused the error
  if (hspi->Instance == SPI2)
  {
    printf("Error in SPI2: ");
  }
  else if (hspi->Instance == SPI3)
  {
    printf("Error in SPI3: ");
  }
  else if (hspi->Instance == SPI4)
  {
    printf("Error in SPI4: ");
  }
  else if (hspi->Instance == SPI6)
  {
    printf("Error in SPI6: ");
  }
  else
  {
    printf("Error in Unknown SPI instance: ");
  }

  // Identify specific errors using error codes
  if (hspi->ErrorCode & HAL_SPI_ERROR_OVR)
  {
    printf("Overrun error ");
    __HAL_SPI_CLEAR_OVRFLAG(hspi);
    if (cam_id >= 0) { cam_overrun_count[cam_id]++; }  /* #68 instrumentation */
  }
  if (hspi->ErrorCode & HAL_SPI_ERROR_MODF)
  {
    printf("Mode fault error ");
  }
  if (hspi->ErrorCode & HAL_SPI_ERROR_CRC)
  {
    printf("CRC error ");
  }
  if (hspi->ErrorCode & HAL_SPI_ERROR_FRE)
  {
    printf("Frame error ");
  }
  if (hspi->ErrorCode & HAL_SPI_ERROR_DMA)
  {
    if (hspi->hdmarx->ErrorCode == HAL_DMA_ERROR_TE)
      printf("TE - HAL_DMA_ERROR_TE");
    if (hspi->hdmarx->ErrorCode == HAL_DMA_ERROR_FE)
      printf("HAL_DMA_ERROR_FE ");
    if (hspi->hdmarx->ErrorCode == HAL_DMA_ERROR_DME)
      printf("HAL_DMA_ERROR_DME");
    if (hspi->hdmarx->ErrorCode == HAL_DMA_ERROR_TIMEOUT)
      printf("HAL_DMA_ERROR_TIMEOUT");
    if (hspi->hdmarx->ErrorCode == HAL_DMA_ERROR_PARAM)
      printf("HAL_DMA_ERROR_PARAM");
    if (hspi->hdmarx->ErrorCode == HAL_DMA_ERROR_NO_XFER)
      printf("HAL_DMA_ERROR_NO_XFER");
    if (hspi->hdmarx->ErrorCode == HAL_DMA_ERROR_NOT_SUPPORTED)
      printf("HAL_DMA_ERROR_NOT_SUPPORTED");
    if (hspi->hdmarx->ErrorCode == HAL_DMA_ERROR_SYNC)
      printf("HAL_DMA_ERROR_SYNC");
    if (hspi->hdmarx->ErrorCode == HAL_DMA_ERROR_REQGEN)
      printf("HAL_DMA_ERROR_REQGEN");
    if (hspi->hdmarx->ErrorCode == HAL_DMA_ERROR_BUSY)
      printf("HAL_DMA_ERROR_BUSY");
  }
  printf("\r\n");

  /* Attempt graceful recovery for any known camera SPI peripheral.
   * Previously only overrun errors were recovered here; all other error types
   * fell through to Error_Handler() which calls __disable_irq() + while(1),
   * killing USB and all other peripherals.  The observed failure mode was:
   *   Camera 6 overheats → SPI3 DMA/frame error (not OVR) →
   *   Error_Handler() entered from interrupt context →
   *   wait_for_usb_queues_to_finish() blocks (USB ISR can't run) →
   *   __disable_irq() → MCU completely dark.
   * #116: recovery is now flag + PendSV re-arm with a main-loop retry
   * backstop — see the USART error callback above for the rationale. */
  if (cam_id >= 0)
  {
    camera_rx_error_recover((uint8_t)cam_id);
    return;
  }

  /* Truly unknown SPI peripheral — log and continue rather than halting. */
  printf("[SPI] Unhandled SPI error on unknown peripheral, continuing.\r\n");
}

/* #116: RX completions run the buffer-exchange protocol in camera_manager.c
 * (publish the filled half, swap the DMA target, pend the PendSV re-arm)
 * instead of just setting an event bit and leaving the re-arm to the send
 * path. Instance -> cam_id mapping matches the old BIT_n assignments. */

// Interrupt handler for SPI reception
// cppcheck-suppress constParameterPointer ; HAL weak callback signature is fixed by the STM32 HAL
void HAL_SPI_RxCpltCallback(SPI_HandleTypeDef *hspi)
{
  if (hspi->Instance == SPI2)
  {
    camera_rx_complete(6);
  }
  else if (hspi->Instance == SPI3)
  {
    camera_rx_complete(5);
  }
  else if (hspi->Instance == SPI4)
  {
    camera_rx_complete(7);
  }
  else if (hspi->Instance == SPI6)
  {
    camera_rx_complete(1);
  }
}

// cppcheck-suppress constParameterPointer ; HAL weak callback signature is fixed by the STM32 HAL
void HAL_USART_RxCpltCallback(USART_HandleTypeDef *husart)
{
  if (husart->Instance == USART1)
  {
    camera_rx_complete(4);
  }
  else if (husart->Instance == USART2)
  {
    camera_rx_complete(0);
  }
  else if (husart->Instance == USART3)
  {
    camera_rx_complete(2);
  }
  else if (husart->Instance == USART6)
  {
    camera_rx_complete(3);
  }

}

// cppcheck-suppress constParameterPointer ; HAL weak callback signature is fixed by the STM32 HAL
void HAL_TIM_PWM_PulseFinishedCallback(TIM_HandleTypeDef *htim)
{
  if (htim->Instance == TIM4) // Call data sender (internal FSIN))
  {
    fsin_timestamp_ms = get_timestamp_ms();  /* #68: stamp the frame at FSIN */
    /* #68 experiment: defer the heavy send to the main loop when enabled. */
    if ((logging_get_debug_flags() & DEBUG_FLAG_SEND_DEFER) != 0u) {
      send_data_flag = true;
    } else {
      send_data();
    }
  }
}

void HAL_GPIO_EXTI_Callback(uint16_t GPIO_Pin)
{
    if (GPIO_Pin == GPIO_PIN_13) // Call REAL data sender if interrupt hit and enabled
    {
      pulse_count++;
      fsin_timestamp_ms = get_timestamp_ms();  /* #68: stamp the frame at the FSIN rising edge */
      /* #68 experiment: defer the heavy send to the main loop when enabled. */
      if ((logging_get_debug_flags() & DEBUG_FLAG_SEND_DEFER) != 0u) {
        send_data_flag = true;
      } else {
        send_data();
      }
    }
}

void ExitRun0Mode(void) {
    // Temporary stub for ExitRun0Mode
}

/**
 * @brief Wait for all USB data queues to finish sending
 * @note This function polls USB endpoint status flags until all transmissions complete
 *       or a timeout occurs. This ensures error messages and diagnostic data are
 *       transmitted before the system halts.
 */
static void wait_for_usb_queues_to_finish(void)
{
  const uint32_t timeout_ms = 1000;  // Maximum wait time: 1 second
  uint32_t start_time = get_timestamp_ms();
  uint32_t elapsed = 0;

  printf("Waiting for USB queues to finish...\r\n");
  fflush(stdout);

  // Poll until all endpoints are idle or timeout
  while (elapsed < timeout_ms) {
    _Bool all_idle = true;

    // Check COMMS endpoint (tx_flag: 1 = idle, 0 = busy)
    if (tx_flag == 0) {
      all_idle = false;
    }

    // Check COMMS bulk endpoint (comms_ep_data: 0 = idle, 1 = transmitting)
    if (comms_ep_data != 0) {
      all_idle = false;
    }

    // Check HISTO endpoint (histo_ep_data: 0 = idle, 1 = transmitting)
    if (histo_ep_data != 0) {
      all_idle = false;
    }

    // Check IMU endpoint (imu_ep_data: 0 = idle, 1 = transmitting)
    if (imu_ep_data != 0) {
      all_idle = false;
    }

    if (all_idle) {
      printf("All USB queues finished.\r\n");
      fflush(stdout);
      return;
    }

    // Small delay to avoid busy-waiting
    delay_ms(1);
    elapsed = get_timestamp_ms() - start_time;
  }

  printf("USB queue wait timeout after %lu ms (some data may not have been sent).\r\n", elapsed);
  fflush(stdout);
}

/* HAL_RAMECC_DetectErrorCallback is implemented in system_monitor.c */

/**
 * @brief Service one pending IMU sample (set by the TIM14 ISR at 40 Hz —
 *        one sample per camera frame, matching the configured 17 Hz DLPF).
 * @note  Runs in the main loop so the ~1.4 ms blocking ICM read and any
 *        error printf happen in thread context, where the USB IRQ can
 *        preempt. If the loop is busy for more than one tick the missed
 *        samples are dropped (visible as gaps in the stream's F counter).
 */
static void imu_service(void)
{
  if (!imu_sample_due) {
    return;
  }
  imu_sample_due = 0;

  /* hi2c1 is shared with the TCA9548A camera mux and the camera sensors,
   * but every user runs here in the main loop — the frame ISRs only set
   * flags (see camera_i2c_service()) — so this blocking read can't
   * interleave with another transaction and needs no IRQ masking. */
  uint8_t read_status = ICM_GetAllRawData(&a, &t, &g, &m);

  if (read_status != HAL_OK) {
    /* A flaky ICM fails every tick at 40 Hz — keep the signal, drop the
     * volume (same pattern as the FSIN debounce warning). */
    static uint32_t imu_read_err_count = 0;
    imu_read_err_count++;
    if ((imu_read_err_count & 0xFF) == 1) {
      printf("IMU Read Error (%lu so far)\r\n", (unsigned long)imu_read_err_count);
    }
    return;
  }

  uint32_t frame = imu_frame_counter;
  memset(usb_buf, 0, 128);
  int len = snprintf(
      usb_buf, sizeof(usb_buf),
      "{\"F\":%lu,\"G\":[%d,%d,%d],\"M\":[%d,%d,%d],\"A\":[%d,%d,%d],\"T\":%d.%02d}\r\n",
      (unsigned long)frame,
      g.x, g.y, g.z,
      m.x, m.y, m.z,
      a.x, a.y, a.z,
      (int)t, (int)((t - (int)t) * 100.0f)
  );
  USBD_IMU_SetTxBuffer(&hUsbDeviceHS, (uint8_t *)usb_buf, len);
}

/* USER CODE END 4 */

 /* MPU Configuration */

void MPU_Config(void)
{
  MPU_Region_InitTypeDef MPU_InitStruct = {0};

  /* Disables the MPU */
  HAL_MPU_Disable();

  /** Initializes and configures the Region and the memory to be protected
  */
  MPU_InitStruct.Enable = MPU_REGION_ENABLE;
  MPU_InitStruct.Number = MPU_REGION_NUMBER0;
  MPU_InitStruct.BaseAddress = 0x0;
  MPU_InitStruct.Size = MPU_REGION_SIZE_4GB;
  MPU_InitStruct.SubRegionDisable = 0x87;
  MPU_InitStruct.TypeExtField = MPU_TEX_LEVEL0;
  MPU_InitStruct.AccessPermission = MPU_REGION_NO_ACCESS;
  MPU_InitStruct.DisableExec = MPU_INSTRUCTION_ACCESS_DISABLE;
  MPU_InitStruct.IsShareable = MPU_ACCESS_SHAREABLE;
  MPU_InitStruct.IsCacheable = MPU_ACCESS_NOT_CACHEABLE;
  MPU_InitStruct.IsBufferable = MPU_ACCESS_NOT_BUFFERABLE;

  HAL_MPU_ConfigRegion(&MPU_InitStruct);
  /* Enables the MPU */
  HAL_MPU_Enable(MPU_PRIVILEGED_DEFAULT);

}

void HAL_TIM_PeriodElapsedCallback(TIM_HandleTypeDef *htim)
{
  if (htim->Instance == TIM17)
  {
    HAL_IncTick();
  }
  /* USER CODE BEGIN Callback 1 */
  if (htim->Instance == TIM16){
	  HistoFake_GenerateAndSend(&hUsbDeviceHS);
  }

  if (htim->Instance == TIM14)
  {
	  /* No I2C and no printf in here: this ISR runs at preemption priority
	   * 0, same as the USB OTG_HS IRQ, so anything that waits on USB (the
	   * USB log path does) can never complete and wedges the CPU in this
	   * ISR (2026-06-11 IMU streaming wedge). The main loop samples via
	   * imu_service(). Counting ticks here keeps frame numbers honest:
	   * gaps in F reveal samples the main loop couldn't service in time. */
	  imu_frame_counter++;
	  imu_sample_due = 1;
  }

  if (htim->Instance == TIM15) {
    HAL_TIM_Base_Stop_IT(htim);
    if(_enter_dfu) {
#if defined(BARE_METAL_BUILD)
      /* Bare-metal build: no custom bootloader. Arm the RAM magic that
       * CheckBootloaderFlag() (system_stm32h7xx.c) reads after the reset below;
       * it then jumps to the STM32 system-memory ROM DFU loader. D3 SRAM
       * survives the software reset. */
      *((uint32_t *)0x38000000) = 0xDEADBEEFU;
      __DSB();
#else
      /* Custom-bootloader build: request DFU from our secure bootloader (NOT the
       * STM32 ROM loader). It reads RTC->BKP7R on the next reset and, when it
       * holds the magic, enters USB DFU instead of launching the app. The backup
       * register lives in the VBAT/backup domain and survives the reset below.
       * Direct CMSIS access (HAL RTC module not enabled): unlock backup domain
       * (DBP), clock the RTC APB interface + kernel (LSI), then arm the magic. */
      PWR->CR1     |= PWR_CR1_DBP;
      RCC->APB4ENR |= RCC_APB4ENR_RTCAPBEN;
      RCC->CSR     |= RCC_CSR_LSION;
      { uint32_t to = 0U;
        while (((RCC->CSR & RCC_CSR_LSIRDY) == 0U) && (++to < 0x00100000U)) { } }
      if ((RCC->BDCR & RCC_BDCR_RTCSEL) == 0U) {
        RCC->BDCR = (RCC->BDCR & ~RCC_BDCR_RTCSEL) | RCC_BDCR_RTCSEL_1; /* LSI */
      }
      RCC->BDCR |= RCC_BDCR_RTCEN;
      RTC->BKP7R = 0xB007C0DEU;   /* BL_FORCE_DFU_MAGIC */
      __DSB();
#endif
    }

    // De-initialize other specific modules
    HAL_RNG_DeInit(&hrng);
    HAL_CRC_DeInit(&hcrc);

    /* Record the reason before the wait: the wait runs in this ISR, where
     * nothing else feeds IWDG1, and a mark left until after it would be lost
     * to a watchdog reset as "unexpected" (#136, #137). */
    system_monitor_mark_shutdown(_enter_dfu ? SYSMON_SHUTDOWN_HOST_DFU
                                            : SYSMON_SHUTDOWN_HOST_RESET);
    MX_USB_DEVICE_DeInit();
    delay_ms_fed(300);
    // Reset the board
    NVIC_SystemReset();

  }

  /* USER CODE END Callback 1 */
}

void Error_Handler(void)
{
  /* USER CODE BEGIN Error_Handler_Debug */
  /* User can add his own implementation to report the HAL error return state */

  /* #137: first, so the next boot reports it even if the prints below hang. */
  system_monitor_mark_shutdown(SYSMON_SHUTDOWN_ERROR_HANDLER);

  const uint32_t *stack_ptr;

  HAL_GPIO_TogglePin(ERROR_LED_GPIO_Port, ERROR_LED_Pin);
  printf(">>> HARD FAULT <<<\r\n");
  fflush(stdout); // Ensure the output is flushed immediately

  // Get the current stack pointer
  __ASM volatile("MRS %0, MSP" : "=r"(stack_ptr));

  // Print general-purpose registers
  printf("Stack Pointer (MSP): 0x%08lX\r\n", (unsigned long)stack_ptr);
  printf("Register dump:\r\n");
  printf("R0 : 0x%08lX\r\n", stack_ptr[0]);
  printf("R1 : 0x%08lX\r\n", stack_ptr[1]);
  printf("R2 : 0x%08lX\r\n", stack_ptr[2]);
  printf("R3 : 0x%08lX\r\n", stack_ptr[3]);
  printf("R12: 0x%08lX\r\n", stack_ptr[4]);
  printf("LR : 0x%08lX (Link Register)\r\n", stack_ptr[5]);
  printf("PC : 0x%08lX (Program Counter)\r\n", stack_ptr[6]);
  printf("xPSR: 0x%08lX\r\n", stack_ptr[7]);
  fflush(stdout);

  // Wait for all USB data queues to finish sending before halting
  wait_for_usb_queues_to_finish();

  delay_ms(100);
  __disable_irq();
  while (1)
  {
  }
  /* USER CODE END Error_Handler_Debug */
}
